[part 1 of 2: package /STELLANTIS/EPT/COMSWCs]
AUTOSAR XML (schema 4-2-2)
package /STELLANTIS/EPT/COMSWCs
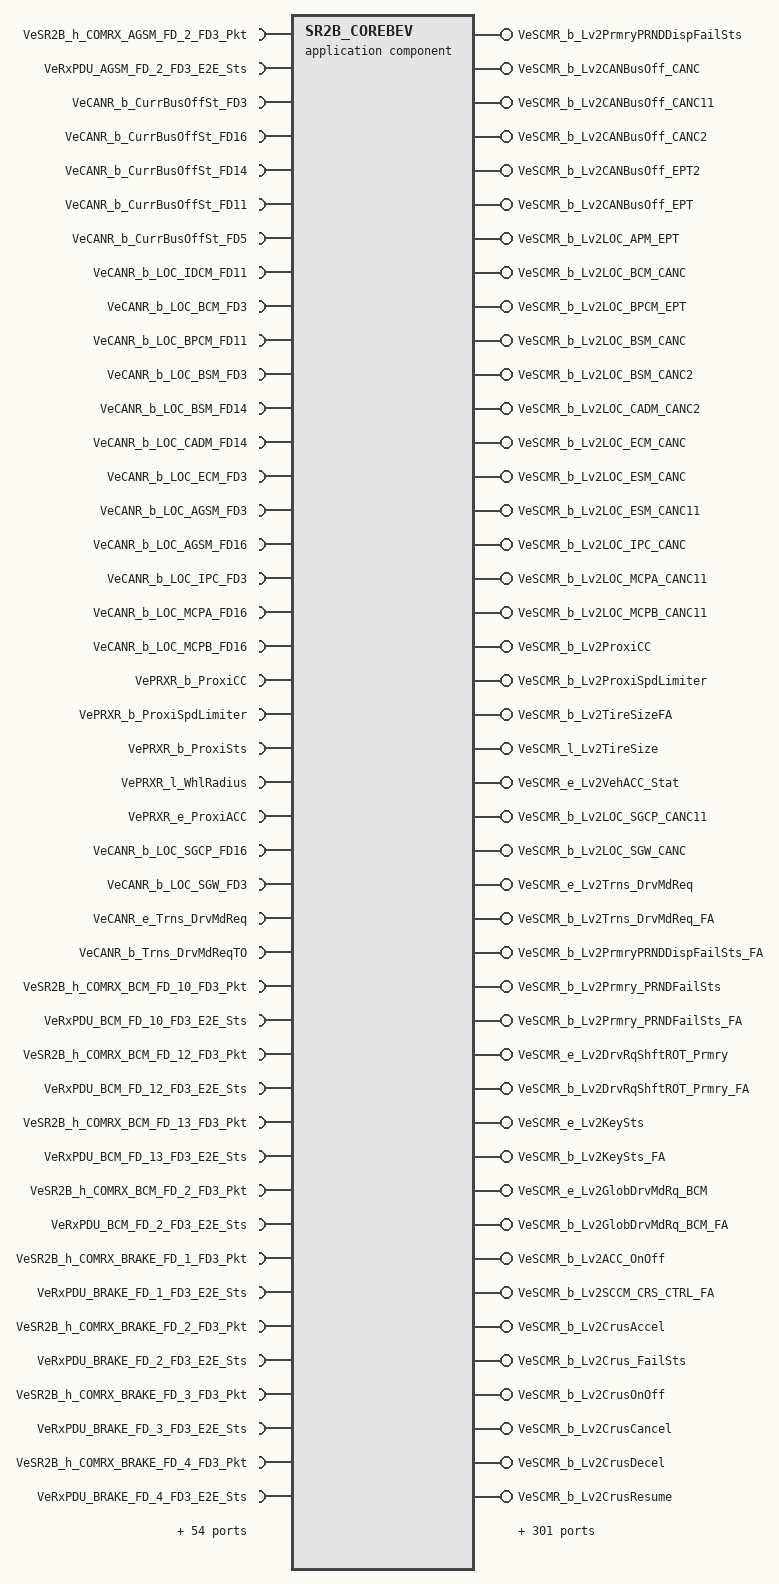
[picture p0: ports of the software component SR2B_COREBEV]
  application sw component type SR2B_COREBEV
    98 x require port:
      VeSR2B_h_COMRX_AGSM_FD_2_FD3_Pkt: nonqueued-receiver-com-spec{data-element=COMRX_AGSM_FD_2_FD3_Pkt, alive-timeout=0.2, init-value={short-label=DefaultInitValue_IDTRAGSM_FD_2_FD3_Pkt, fields=[0, 0, 0, 0, 0]}}, required-interface=VeSR2B_h_COMRX_AGSM_FD_2_FD3_Pkt
      VeRxPDU_AGSM_FD_2_FD3_E2E_Sts: required-com-specs=[{data-element=E2ECheckSts, init-value=0}, {data-element=OpRetVal, init-value=0}], required-interface=VeRxPDU_AGSM_FD_2_FD3_E2E_Sts
      VeCANR_b_CurrBusOffSt_FD3: nonqueued-receiver-com-spec{data-element=VeCANR_b_CurrBusOffSt_FD3, init-value=0}, required-interface=VeCANR_b_CurrBusOffSt_FD3
      VeCANR_b_CurrBusOffSt_FD16: nonqueued-receiver-com-spec{data-element=VeCANR_b_CurrBusOffSt_FD16, init-value=0}, required-interface=VeCANR_b_CurrBusOffSt_FD16
      VeCANR_b_CurrBusOffSt_FD14: nonqueued-receiver-com-spec{data-element=VeCANR_b_CurrBusOffSt_FD14, init-value=0}, required-interface=VeCANR_b_CurrBusOffSt_FD14
      VeCANR_b_CurrBusOffSt_FD11: nonqueued-receiver-com-spec{data-element=VeCANR_b_CurrBusOffSt_FD11, init-value=0}, required-interface=VeCANR_b_CurrBusOffSt_FD11
      VeCANR_b_CurrBusOffSt_FD5: nonqueued-receiver-com-spec{data-element=VeCANR_b_CurrBusOffSt_FD5, init-value=0}, required-interface=VeCANR_b_CurrBusOffSt_FD5
      VeCANR_b_LOC_IDCM_FD11: nonqueued-receiver-com-spec{data-element=VeCANR_b_LOC_IDCM_FD11, init-value=0}, required-interface=VeCANR_b_LOC_IDCM_FD11
      VeCANR_b_LOC_BCM_FD3: nonqueued-receiver-com-spec{data-element=VeCANR_b_LOC_BCM_FD3, init-value=0}, required-interface=VeCANR_b_LOC_BCM_FD3
      VeCANR_b_LOC_BPCM_FD11: nonqueued-receiver-com-spec{data-element=VeCANR_b_LOC_BPCM_FD11, init-value=0}, required-interface=VeCANR_b_LOC_BPCM_FD11
      VeCANR_b_LOC_BSM_FD3: nonqueued-receiver-com-spec{data-element=VeCANR_b_LOC_BSM_FD3, init-value=0}, required-interface=VeCANR_b_LOC_BSM_FD3
      VeCANR_b_LOC_BSM_FD14: nonqueued-receiver-com-spec{data-element=VeCANR_b_LOC_BSM_FD14, init-value=0}, required-interface=VeCANR_b_LOC_BSM_FD14
      VeCANR_b_LOC_CADM_FD14: nonqueued-receiver-com-spec{data-element=VeCANR_b_LOC_CADM_FD14, init-value=0}, required-interface=VeCANR_b_LOC_CADM_FD14
      VeCANR_b_LOC_ECM_FD3: nonqueued-receiver-com-spec{data-element=VeCANR_b_LOC_ECM_FD3, init-value=0}, required-interface=VeCANR_b_LOC_ECM_FD3
      VeCANR_b_LOC_AGSM_FD3: nonqueued-receiver-com-spec{data-element=VeCANR_b_LOC_AGSM_FD3, init-value=0}, required-interface=VeCANR_b_LOC_AGSM_FD3
      VeCANR_b_LOC_AGSM_FD16: nonqueued-receiver-com-spec{data-element=VeCANR_b_LOC_AGSM_FD16, init-value=0}, required-interface=VeCANR_b_LOC_AGSM_FD16
      VeCANR_b_LOC_IPC_FD3: nonqueued-receiver-com-spec{data-element=VeCANR_b_LOC_IPC_FD3, init-value=0}, required-interface=VeCANR_b_LOC_IPC_FD3
      VeCANR_b_LOC_MCPA_FD16: nonqueued-receiver-com-spec{data-element=VeCANR_b_LOC_MCPA_FD16, init-value=0}, required-interface=VeCANR_b_LOC_MCPA_FD16
      VeCANR_b_LOC_MCPB_FD16: nonqueued-receiver-com-spec{data-element=VeCANR_b_LOC_MCPB_FD16, init-value=0}, required-interface=VeCANR_b_LOC_MCPB_FD16
      VePRXR_b_ProxiCC: nonqueued-receiver-com-spec{data-element=Value, init-value=0}, required-interface=VePRXR_b_ProxiCC
      VePRXR_b_ProxiSpdLimiter: nonqueued-receiver-com-spec{data-element=Value, init-value=0}, required-interface=VePRXR_b_ProxiSpdLimiter
      VePRXR_b_ProxiSts: nonqueued-receiver-com-spec{data-element=Value, init-value=0}, required-interface=VePRXR_b_ProxiSts
      VePRXR_l_WhlRadius: nonqueued-receiver-com-spec{data-element=Value, init-value=0}, required-interface=VePRXR_l_WhlRadius
      VePRXR_e_ProxiACC: nonqueued-receiver-com-spec{data-element=Value, init-value=CePRXR_e_ACC_Absent}, required-interface=VePRXR_e_ProxiACC
      VeCANR_b_LOC_SGCP_FD16: nonqueued-receiver-com-spec{data-element=VeCANR_b_LOC_SGCP_FD16, init-value=0}, required-interface=VeCANR_b_LOC_SGCP_FD16
      VeCANR_b_LOC_SGW_FD3: nonqueued-receiver-com-spec{data-element=VeCANR_b_LOC_SGW_FD3, init-value=0}, required-interface=VeCANR_b_LOC_SGW_FD3
      VeCANR_e_Trns_DrvMdReq: nonqueued-receiver-com-spec{data-element=VeCANR_e_Trns_DrvMdReq, handle-never-received=true, init-value=0}, required-interface=VeCANR_e_Trns_DrvMdReq
      VeCANR_b_Trns_DrvMdReqTO: nonqueued-receiver-com-spec{data-element=VeCANR_b_Trns_DrvMdReqTO, init-value=0}, required-interface=VeCANR_b_Trns_DrvMdReqTO
      VeSR2B_h_COMRX_BCM_FD_10_FD3_Pkt: nonqueued-receiver-com-spec{data-element=COMRX_BCM_FD_10_FD3_Pkt, alive-timeout=5, init-value={short-label=DefaultInitValue_IDTRBCM_FD_10_FD3_Pkt, fields=[0, 0, 0, 0, 0]}}, required-interface=VeSR2B_h_COMRX_BCM_FD_10_FD3_Pkt
      VeRxPDU_BCM_FD_10_FD3_E2E_Sts: required-com-specs=[{data-element=E2ECheckSts, init-value=0}, {data-element=OpRetVal, init-value=0}], required-interface=VeRxPDU_BCM_FD_10_FD3_E2E_Sts
      VeSR2B_h_COMRX_BCM_FD_12_FD3_Pkt: nonqueued-receiver-com-spec{data-element=COMRX_BCM_FD_12_FD3_Pkt, alive-timeout=1, init-value={short-label=DefaultInitValue_IDTRBCM_FD_12_FD3_Pkt, fields=[0, 0, 0, 0, 0, 0, 0, 0, 0, 0, 0, 0, 0, 0, 0, 0, 0]}}, required-interface=VeSR2B_h_COMRX_BCM_FD_12_FD3_Pkt
      VeRxPDU_BCM_FD_12_FD3_E2E_Sts: required-com-specs=[{data-element=E2ECheckSts, init-value=0}, {data-element=OpRetVal, init-value=0}], required-interface=VeRxPDU_BCM_FD_12_FD3_E2E_Sts
      VeSR2B_h_COMRX_BCM_FD_13_FD3_Pkt: nonqueued-receiver-com-spec{data-element=COMRX_BCM_FD_13_FD3_Pkt, init-value={short-label=DefaultInitValue_IDTRBCM_FD_13_FD3_Pkt, fields=[0, 0, 0, 0, 0, 0, 0, 0, 0]}}, required-interface=VeSR2B_h_COMRX_BCM_FD_13_FD3_Pkt
      VeRxPDU_BCM_FD_13_FD3_E2E_Sts: required-com-specs=[{data-element=E2ECheckSts, init-value=0}, {data-element=OpRetVal, init-value=0}], required-interface=VeRxPDU_BCM_FD_13_FD3_E2E_Sts
      VeSR2B_h_COMRX_BCM_FD_2_FD3_Pkt: nonqueued-receiver-com-spec{data-element=COMRX_BCM_FD_2_FD3_Pkt, alive-timeout=0.1, init-value={short-label=DefaultInitValue_IDTRBCM_FD_2_FD3_Pkt, fields=[0, 0, 0, 0, 0]}}, required-interface=VeSR2B_h_COMRX_BCM_FD_2_FD3_Pkt
      VeRxPDU_BCM_FD_2_FD3_E2E_Sts: required-com-specs=[{data-element=E2ECheckSts, init-value=0}, {data-element=OpRetVal, init-value=0}], required-interface=VeRxPDU_BCM_FD_2_FD3_E2E_Sts
      VeSR2B_h_COMRX_BRAKE_FD_1_FD3_Pkt: nonqueued-receiver-com-spec{data-element=COMRX_BRAKE_FD_1_FD3_Pkt, alive-timeout=0.2, init-value={short-label=DefaultInitValue_IDTRBRAKE_FD_1_FD3_Pkt, fields=[0, 0, 0, 0, 0, 0, 0, 0, 0, 0, 0, 0, 0]}}, required-interface=VeSR2B_h_COMRX_BRAKE_FD_1_FD3_Pkt
      VeRxPDU_BRAKE_FD_1_FD3_E2E_Sts: required-com-specs=[{data-element=E2ECheckSts, init-value=0}, {data-element=OpRetVal, init-value=0}], required-interface=VeRxPDU_BRAKE_FD_1_FD3_E2E_Sts
      VeSR2B_h_COMRX_BRAKE_FD_2_FD3_Pkt: nonqueued-receiver-com-spec{data-element=COMRX_BRAKE_FD_2_FD3_Pkt, alive-timeout=0.1, init-value={short-label=DefaultInitValue_IDTRBRAKE_FD_2_FD3_Pkt, fields=[0, 0, 0, 0, 0, 0, 0, 0, 0, 0, 0, 0, 0, 0, 0, 0, 0, 0]}}, required-interface=VeSR2B_h_COMRX_BRAKE_FD_2_FD3_Pkt
      VeRxPDU_BRAKE_FD_2_FD3_E2E_Sts: required-com-specs=[{data-element=E2ECheckSts, init-value=0}, {data-element=OpRetVal, init-value=0}], required-interface=VeRxPDU_BRAKE_FD_2_FD3_E2E_Sts
      VeSR2B_h_COMRX_BRAKE_FD_3_FD3_Pkt: nonqueued-receiver-com-spec{data-element=COMRX_BRAKE_FD_3_FD3_Pkt, alive-timeout=0.1, init-value={short-label=DefaultInitValue_IDTRBRAKE_FD_3_FD3_Pkt, fields=[0, 0, 0, 0, 0, 0, 0, 0, 0, 0, 0, 0, 0, 0, 0, 0]}}, required-interface=VeSR2B_h_COMRX_BRAKE_FD_3_FD3_Pkt
      VeRxPDU_BRAKE_FD_3_FD3_E2E_Sts: required-com-specs=[{data-element=E2ECheckSts, init-value=0}, {data-element=OpRetVal, init-value=0}], required-interface=VeRxPDU_BRAKE_FD_3_FD3_E2E_Sts
      VeSR2B_h_COMRX_BRAKE_FD_4_FD3_Pkt: nonqueued-receiver-com-spec{data-element=COMRX_BRAKE_FD_4_FD3_Pkt, alive-timeout=1, init-value={short-label=DefaultInitValue_IDTRBRAKE_FD_4_FD3_Pkt, fields=[0, 0, 0, 0]}}, required-interface=VeSR2B_h_COMRX_BRAKE_FD_4_FD3_Pkt
      VeRxPDU_BRAKE_FD_4_FD3_E2E_Sts: required-com-specs=[{data-element=E2ECheckSts, init-value=0}, {data-element=OpRetVal, init-value=0}], required-interface=VeRxPDU_BRAKE_FD_4_FD3_E2E_Sts
      VeSR2B_h_COMRX_BRAKE_FD_5_FD3_Pkt: nonqueued-receiver-com-spec{data-element=COMRX_BRAKE_FD_5_FD3_Pkt, alive-timeout=5, init-value={short-label=DefaultInitValue_IDTRBRAKE_FD_5_FD3_Pkt, fields=[0, 0, 0, 0, 0, 0, 0]}}, required-interface=VeSR2B_h_COMRX_BRAKE_FD_5_FD3_Pkt
      VeRxPDU_BRAKE_FD_5_FD3_E2E_Sts: required-com-specs=[{data-element=E2ECheckSts, init-value=0}, {data-element=OpRetVal, init-value=0}], required-interface=VeRxPDU_BRAKE_FD_5_FD3_E2E_Sts
      VeSR2B_h_COMRX_BRAKE_FD_6_FD3_Pkt: nonqueued-receiver-com-spec{data-element=COMRX_BRAKE_FD_6_FD3_Pkt, alive-timeout=0.1, init-value={short-label=DefaultInitValue_IDTRBRAKE_FD_6_FD3_Pkt, fields=[0, 0, 0, 0, 0, 0, 0, 0, 0, 0, 0, 0, 0, 0]}}, required-interface=VeSR2B_h_COMRX_BRAKE_FD_6_FD3_Pkt
      VeRxPDU_BRAKE_FD_6_FD3_E2E_Sts: required-com-specs=[{data-element=E2ECheckSts, init-value=0}, {data-element=OpRetVal, init-value=0}], required-interface=VeRxPDU_BRAKE_FD_6_FD3_E2E_Sts
      VeSR2B_h_COMRX_BRAKE_FD_7_FD3_Pkt: nonqueued-receiver-com-spec{data-element=COMRX_BRAKE_FD_7_FD3_Pkt, alive-timeout=0.2, init-value={short-label=DefaultInitValue_IDTRBRAKE_FD_7_FD3_Pkt, fields=[0, 0, 0, 0, 0, 0]}}, required-interface=VeSR2B_h_COMRX_BRAKE_FD_7_FD3_Pkt
      VeRxPDU_BRAKE_FD_7_FD3_E2E_Sts: required-com-specs=[{data-element=E2ECheckSts, init-value=0}, {data-element=OpRetVal, init-value=0}], required-interface=VeRxPDU_BRAKE_FD_7_FD3_E2E_Sts
      VeSR2B_h_COMRX_ENGINE_HYBD_FD_1_FD3_Pkt: nonqueued-receiver-com-spec{data-element=COMRX_ENGINE_HYBD_FD_1_FD3_Pkt, alive-timeout=0.1, init-value={short-label=DefaultInitValue_IDTRENGINE_HYBD_FD_1_FD3_Pkt, fields=[0, 0, 0, 0, 0, 0, 0, 0, 0, 0, 0, 0]}}, required-interface=VeSR2B_h_COMRX_ENGINE_HYBD_FD_1_FD3_Pkt
      VeRxPDU_ENGINE_HYBD_FD_1_FD3_E2E_Sts: required-com-specs=[{data-element=E2ECheckSts, init-value=0}, {data-element=OpRetVal, init-value=0}], required-interface=VeRxPDU_ENGINE_HYBD_FD_1_FD3_E2E_Sts
      VeSR2B_h_COMRX_IPC_VEHICLE_SETUP_FD3_Pkt: nonqueued-receiver-com-spec{data-element=COMRX_IPC_VEHICLE_SETUP_FD3_Pkt, alive-timeout=10, init-value={short-label=DefaultInitValue_IDTRIPC_VEHICLE_SETUP_FD3_Pkt, fields=[0, 0, 0, 0, 0, 0, 0]}}, required-interface=VeSR2B_h_COMRX_IPC_VEHICLE_SETUP_FD3_Pkt
      VeRxPDU_IPC_VEHICLE_SETUP_FD3_E2E_Sts: required-com-specs=[{data-element=E2ECheckSts, init-value=0}, {data-element=OpRetVal, init-value=0}], required-interface=VeRxPDU_IPC_VEHICLE_SETUP_FD3_E2E_Sts
      VeSR2B_h_COMRX_TELEMATIC_FD_5_FD3_Pkt: nonqueued-receiver-com-spec{data-element=COMRX_TELEMATIC_FD_5_FD3_Pkt, alive-timeout=10, init-value={short-label=DefaultInitValue_IDTRTELEMATIC_FD_5_FD3_Pkt, fields=0}}, required-interface=VeSR2B_h_COMRX_TELEMATIC_FD_5_FD3_Pkt
      VeRxPDU_TELEMATIC_FD_5_FD3_E2E_Sts: required-com-specs=[{data-element=E2ECheckSts, init-value=0}, {data-element=OpRetVal, init-value=0}], required-interface=VeRxPDU_TELEMATIC_FD_5_FD3_E2E_Sts
      VeSR2B_h_COMRX_APM_VDCM_FD11_Pkt: nonqueued-receiver-com-spec{data-element=COMRX_APM_VDCM_FD11_Pkt, alive-timeout=0.2, init-value={short-label=DefaultInitValue_IDTRAPM_VDCM_FD11_Pkt, fields=[0, 0, 0, 0, 0, 0, 0, 0, 0, 0, 0, 0, 0, 0, 0, 0, 0, 0, 0, 0, 0, 0, 0, 0, 0, 0]}}, required-interface=VeSR2B_h_COMRX_APM_VDCM_FD11_Pkt
      VeRxPDU_APM_VDCM_FD11_E2E_Sts: required-com-specs=[{data-element=E2ECheckSts, init-value=0}, {data-element=OpRetVal, init-value=0}], required-interface=VeRxPDU_APM_VDCM_FD11_E2E_Sts
      VeSR2B_h_COMRX_BATTERY_HV_POWERLIMITS_FD11_Pkt: nonqueued-receiver-com-spec{data-element=COMRX_BATTERY_HV_POWERLIMITS_FD11_Pkt, alive-timeout=0.1, init-value={short-label=DefaultInitValue_IDTRBATTERY_HV_POWERLIMITS_FD11_Pkt, fields=[0, 0, 0, 0, 0, 0, 0, 0, 0, 0, 0, 0, 0, 0, 0, 0]}}, required-interface=VeSR2B_h_COMRX_BATTERY_HV_POWERLIMITS_FD11_Pkt
      VeRxPDU_BATTERY_HV_POWERLIMITS_FD11_E2E_Sts: required-com-specs=[{data-element=E2ECheckSts, init-value=0}, {data-element=OpRetVal, init-value=0}], required-interface=VeRxPDU_BATTERY_HV_POWERLIMITS_FD11_E2E_Sts
      VeSR2B_h_COMRX_BATTERY_HV_STATUS1_FD11_Pkt: nonqueued-receiver-com-spec{data-element=COMRX_BATTERY_HV_STATUS1_FD11_Pkt, alive-timeout=0.1, init-value={short-label=DefaultInitValue_IDTRBATTERY_HV_STATUS1_FD11_Pkt, fields=[0, 0, 0, 0, 0, 0, 0, 0, 0, 0, 0, 0, 0, 0, 0, 0, 0, 0, 0, 0, 0, 0, 0, 0, 0, 0, 0, 0, 0, 0, 0, 0, 0, 0, 0, 0, 0, 0, 0, 0, 0]}}, required-interface=VeSR2B_h_COMRX_BATTERY_HV_STATUS1_FD11_Pkt
      VeRxPDU_BATTERY_HV_STATUS1_FD11_E2E_Sts: required-com-specs=[{data-element=E2ECheckSts, init-value=0}, {data-element=OpRetVal, init-value=0}], required-interface=VeRxPDU_BATTERY_HV_STATUS1_FD11_E2E_Sts
      VeSR2B_h_COMRX_HV_CHARGER1_FD11_Pkt: nonqueued-receiver-com-spec{data-element=COMRX_HV_CHARGER1_FD11_Pkt, alive-timeout=1, init-value={short-label=DefaultInitValue_IDTRHV_CHARGER1_FD11_Pkt, fields=[0, 0, 0, 0, 0, 0, 0, 0, 0, 0, 0, 0, 0, 0, 0, 0, 0, 0, 0, 0, 0, 0, 0, 0, 0, 0, 0, 0, 0, 0, 0, 0, 0, 0, 0, 0, 0]}}, required-interface=VeSR2B_h_COMRX_HV_CHARGER1_FD11_Pkt
      VeRxPDU_HV_CHARGER1_FD11_E2E_Sts: required-com-specs=[{data-element=E2ECheckSts, init-value=0}, {data-element=OpRetVal, init-value=0}], required-interface=VeRxPDU_HV_CHARGER1_FD11_E2E_Sts
      VeSR2B_h_COMRX_ADAS_FD_INFO_FD14_Pkt: nonqueued-receiver-com-spec{data-element=COMRX_ADAS_FD_INFO_FD14_Pkt, alive-timeout=0.1, init-value={short-label=DefaultInitValue_IDTRADAS_FD_INFO_FD14_Pkt, fields=[0, 0, 0, 0, 0, 0, 0, 0, 0]}}, required-interface=VeSR2B_h_COMRX_ADAS_FD_INFO_FD14_Pkt
      VeRxPDU_ADAS_FD_INFO_FD14_E2E_Sts: required-com-specs=[{data-element=E2ECheckSts, init-value=0}, {data-element=OpRetVal, init-value=0}], required-interface=VeRxPDU_ADAS_FD_INFO_FD14_E2E_Sts
      VeSR2B_h_COMRX_BRAKE_FD_1_FD14_Pkt: nonqueued-receiver-com-spec{data-element=COMRX_BRAKE_FD_1_FD14_Pkt, alive-timeout=0.2, init-value={short-label=DefaultInitValue_IDTRBRAKE_FD_1_FD14_Pkt, fields=[0, 0, 0, 0, 0, 0, 0, 0]}}, required-interface=VeSR2B_h_COMRX_BRAKE_FD_1_FD14_Pkt
      VeRxPDU_BRAKE_FD_1_FD14_E2E_Sts: required-com-specs=[{data-element=E2ECheckSts, init-value=0}, {data-element=OpRetVal, init-value=0}], required-interface=VeRxPDU_BRAKE_FD_1_FD14_E2E_Sts
      VeSR2B_h_COMRX_BRAKE_FD_2_FD14_Pkt: nonqueued-receiver-com-spec{data-element=COMRX_BRAKE_FD_2_FD14_Pkt, alive-timeout=0.1, init-value={short-label=DefaultInitValue_IDTRBRAKE_FD_2_FD14_Pkt, fields=[0, 0, 0, 0, 0, 0, 0, 0, 0]}}, required-interface=VeSR2B_h_COMRX_BRAKE_FD_2_FD14_Pkt
      VeRxPDU_BRAKE_FD_2_FD14_E2E_Sts: required-com-specs=[{data-element=E2ECheckSts, init-value=0}, {data-element=OpRetVal, init-value=0}], required-interface=VeRxPDU_BRAKE_FD_2_FD14_E2E_Sts
      VeSR2B_h_COMRX_BRAKE_FD_6_FD14_Pkt: nonqueued-receiver-com-spec{data-element=COMRX_BRAKE_FD_6_FD14_Pkt, alive-timeout=0.1, init-value={short-label=DefaultInitValue_IDTRBRAKE_FD_6_FD14_Pkt, fields=[0, 0, 0, 0, 0, 0, 0, 0, 0, 0]}}, required-interface=VeSR2B_h_COMRX_BRAKE_FD_6_FD14_Pkt
      VeRxPDU_BRAKE_FD_6_FD14_E2E_Sts: required-com-specs=[{data-element=E2ECheckSts, init-value=0}, {data-element=OpRetVal, init-value=0}], required-interface=VeRxPDU_BRAKE_FD_6_FD14_E2E_Sts
      VeSR2B_h_COMRX_BRAKE_FD_7_FD14_Pkt: nonqueued-receiver-com-spec{data-element=COMRX_BRAKE_FD_7_FD14_Pkt, alive-timeout=0.2, init-value={short-label=DefaultInitValue_IDTRBRAKE_FD_7_FD14_Pkt, fields=[0, 0, 0]}}, required-interface=VeSR2B_h_COMRX_BRAKE_FD_7_FD14_Pkt
      VeRxPDU_BRAKE_FD_7_FD14_E2E_Sts: required-com-specs=[{data-element=E2ECheckSts, init-value=0}, {data-element=OpRetVal, init-value=0}], required-interface=VeRxPDU_BRAKE_FD_7_FD14_E2E_Sts
      VeSR2B_h_COMRX_EPS_FD_1_FD14_Pkt: nonqueued-receiver-com-spec{data-element=COMRX_EPS_FD_1_FD14_Pkt, alive-timeout=0.1, init-value={short-label=DefaultInitValue_IDTREPS_FD_1_FD14_Pkt, fields=[0, 0, 0]}}, required-interface=VeSR2B_h_COMRX_EPS_FD_1_FD14_Pkt
      VeRxPDU_EPS_FD_1_FD14_E2E_Sts: required-com-specs=[{data-element=E2ECheckSts, init-value=0}, {data-element=OpRetVal, init-value=0}], required-interface=VeRxPDU_EPS_FD_1_FD14_E2E_Sts
      VeSR2B_h_COMRX_ORC_FD_3_FD14_Pkt: nonqueued-receiver-com-spec{data-element=COMRX_ORC_FD_3_FD14_Pkt, alive-timeout=0.1, init-value={short-label=DefaultInitValue_IDTRORC_FD_3_FD14_Pkt, fields=[0, 0, 0, 0, 0, 0]}}, required-interface=VeSR2B_h_COMRX_ORC_FD_3_FD14_Pkt
      VeRxPDU_ORC_FD_3_FD14_E2E_Sts: required-com-specs=[{data-element=E2ECheckSts, init-value=0}, {data-element=OpRetVal, init-value=0}], required-interface=VeRxPDU_ORC_FD_3_FD14_E2E_Sts
      VeSR2B_h_COMRX_AGSM_FD_2_FD16_Pkt: nonqueued-receiver-com-spec{data-element=COMRX_AGSM_FD_2_FD16_Pkt, alive-timeout=0.2, init-value={short-label=DefaultInitValue_IDTRAGSM_FD_2_FD16_Pkt, fields=[0, 0, 0, 0]}}, required-interface=VeSR2B_h_COMRX_AGSM_FD_2_FD16_Pkt
      VeRxPDU_AGSM_FD_2_FD16_E2E_Sts: required-com-specs=[{data-element=E2ECheckSts, init-value=0}, {data-element=OpRetVal, init-value=0}], required-interface=VeRxPDU_AGSM_FD_2_FD16_E2E_Sts
      VeSR2B_h_COMRX_ELSDM_FD_1_FD16_Pkt: nonqueued-receiver-com-spec{data-element=COMRX_ELSDM_FD_1_FD16_Pkt, alive-timeout=0.1, init-value={short-label=DefaultInitValue_IDTRELSDM_FD_1_FD16_Pkt, fields=[0, 0, 0, 0, 0, 0, 0, 0, 0, 0, 0, 0, 0, 0, 0, 0, 0, 0, 0, 0]}}, required-interface=VeSR2B_h_COMRX_ELSDM_FD_1_FD16_Pkt
      VeRxPDU_ELSDM_FD_1_FD16_E2E_Sts: required-com-specs=[{data-element=E2ECheckSts, init-value=0}, {data-element=OpRetVal, init-value=0}], required-interface=VeRxPDU_ELSDM_FD_1_FD16_E2E_Sts
      VeSR2B_h_COMRX_MCPA_PROPULSION_FD16_Pkt: nonqueued-receiver-com-spec{data-element=COMRX_MCPA_PROPULSION_FD16_Pkt, alive-timeout=0.1, init-value={short-label=DefaultInitValue_IDTRMCPA_PROPULSION_FD16_Pkt, fields=[0, 0, 0, 0, 0, 0, 0, 0, 0, 0, 0, 0, 0, 0, 0, 0, 0, 0, 0, 0, 0, 0, 0, 0, 0, 0]}}, required-interface=VeSR2B_h_COMRX_MCPA_PROPULSION_FD16_Pkt
      VeRxPDU_MCPA_PROPULSION_FD16_E2E_Sts: required-com-specs=[{data-element=E2ECheckSts, init-value=0}, {data-element=OpRetVal, init-value=0}], required-interface=VeRxPDU_MCPA_PROPULSION_FD16_E2E_Sts
      VeSR2B_h_COMRX_MCPB_PROPULSION_FD16_Pkt: nonqueued-receiver-com-spec{data-element=COMRX_MCPB_PROPULSION_FD16_Pkt, alive-timeout=0.1, init-value={short-label=DefaultInitValue_IDTRMCPB_PROPULSION_FD16_Pkt, fields=[0, 0, 0, 0, 0, 0, 0, 0, 0, 0, 0, 0, 0, 0, 0, 0, 0, 0, 0, 0, 0, 0, 0, 0, 0, 0, 0, 0, 0, 0, 0]}}, required-interface=VeSR2B_h_COMRX_MCPB_PROPULSION_FD16_Pkt
      VeRxPDU_MCPB_PROPULSION_FD16_E2E_Sts: required-com-specs=[{data-element=E2ECheckSts, init-value=0}, {data-element=OpRetVal, init-value=0}], required-interface=VeRxPDU_MCPB_PROPULSION_FD16_E2E_Sts
      VeSR2B_h_COMRX_APM_VDCM_FD5_Pkt: nonqueued-receiver-com-spec{data-element=COMRX_APM_VDCM_FD5_Pkt, alive-timeout=0.2, init-value={short-label=DefaultInitValue_IDTRAPM_VDCM_FD5_Pkt, fields=[0, 0, 0, 0, 0, 0, 0, 0, 0, 0, 0, 0, 0, 0, 0, 0, 0, 0, 0, 0, 0, 0, 0, 0, 0, 0]}}, required-interface=VeSR2B_h_COMRX_APM_VDCM_FD5_Pkt
      VeRxPDU_APM_VDCM_FD5_E2E_Sts: required-com-specs=[{data-element=E2ECheckSts, init-value=0}, {data-element=OpRetVal, init-value=0}], required-interface=VeRxPDU_APM_VDCM_FD5_E2E_Sts
      VeSR2B_h_COMRX_BATTERY_HV_POWERLIMITS_FD5_Pkt: nonqueued-receiver-com-spec{data-element=COMRX_BATTERY_HV_POWERLIMITS_FD5_Pkt, alive-timeout=0.1, init-value={short-label=DefaultInitValue_IDTRBATTERY_HV_POWERLIMITS_FD5_Pkt, fields=[0, 0, 0, 0, 0, 0, 0, 0, 0, 0, 0, 0, 0, 0, 0, 0]}}, required-interface=VeSR2B_h_COMRX_BATTERY_HV_POWERLIMITS_FD5_Pkt
      VeRxPDU_BATTERY_HV_POWERLIMITS_FD5_E2E_Sts: required-com-specs=[{data-element=E2ECheckSts, init-value=0}, {data-element=OpRetVal, init-value=0}], required-interface=VeRxPDU_BATTERY_HV_POWERLIMITS_FD5_E2E_Sts
      VeSR2B_h_COMRX_BATTERY_HV_STATUS1_FD5_Pkt: nonqueued-receiver-com-spec{data-element=COMRX_BATTERY_HV_STATUS1_FD5_Pkt, alive-timeout=0.1, init-value={short-label=DefaultInitValue_IDTRBATTERY_HV_STATUS1_FD5_Pkt, fields=[0, 0, 0, 0, 0, 0, 0, 0, 0, 0, 0, 0, 0, 0, 0, 0, 0, 0, 0, 0, 0, 0, 0, 0, 0, 0, 0, 0, 0, 0, 0, 0, 0, 0, 0, 0, 0, 0, 0, 0, 0]}}, required-interface=VeSR2B_h_COMRX_BATTERY_HV_STATUS1_FD5_Pkt
      VeRxPDU_BATTERY_HV_STATUS1_FD5_E2E_Sts: required-com-specs=[{data-element=E2ECheckSts, init-value=0}, {data-element=OpRetVal, init-value=0}], required-interface=VeRxPDU_BATTERY_HV_STATUS1_FD5_E2E_Sts
      VeSR2B_h_COMRX_HV_CHARGER1_FD5_Pkt: nonqueued-receiver-com-spec{data-element=COMRX_HV_CHARGER1_FD5_Pkt, alive-timeout=1, init-value={short-label=DefaultInitValue_IDTRHV_CHARGER1_FD5_Pkt, fields=[0, 0, 0, 0, 0, 0, 0, 0, 0, 0, 0, 0, 0, 0, 0, 0, 0, 0, 0, 0, 0, 0, 0, 0, 0, 0, 0, 0, 0, 0, 0, 0, 0, 0, 0, 0, 0]}}, required-interface=VeSR2B_h_COMRX_HV_CHARGER1_FD5_Pkt
      VeRxPDU_HV_CHARGER1_FD5_E2E_Sts: required-com-specs=[{data-element=E2ECheckSts, init-value=0}, {data-element=OpRetVal, init-value=0}], required-interface=VeRxPDU_HV_CHARGER1_FD5_E2E_Sts
      VeSR2B_h_COMRX_MCPA_PROPULSION_FD5_Pkt: nonqueued-receiver-com-spec{data-element=COMRX_MCPA_PROPULSION_FD5_Pkt, alive-timeout=0.1, init-value={short-label=DefaultInitValue_IDTRMCPA_PROPULSION_FD5_Pkt, fields=[0, 0, 0, 0, 0, 0, 0, 0, 0, 0, 0, 0, 0, 0, 0, 0, 0, 0, 0, 0, 0, 0, 0, 0, 0, 0]}}, required-interface=VeSR2B_h_COMRX_MCPA_PROPULSION_FD5_Pkt
      VeRxPDU_MCPA_PROPULSION_FD5_E2E_Sts: required-com-specs=[{data-element=E2ECheckSts, init-value=0}, {data-element=OpRetVal, init-value=0}], required-interface=VeRxPDU_MCPA_PROPULSION_FD5_E2E_Sts
      VeSR2B_h_COMRX_MCPB_PROPULSION_FD5_Pkt: nonqueued-receiver-com-spec{data-element=COMRX_MCPB_PROPULSION_FD5_Pkt, alive-timeout=0.1, init-value={short-label=DefaultInitValue_IDTRMCPB_PROPULSION_FD5_Pkt, fields=[0, 0, 0, 0, 0, 0, 0, 0, 0, 0, 0, 0, 0, 0, 0, 0, 0, 0, 0, 0, 0, 0, 0, 0, 0, 0, 0, 0, 0, 0, 0]}}, required-interface=VeSR2B_h_COMRX_MCPB_PROPULSION_FD5_Pkt
      VeRxPDU_MCPB_PROPULSION_FD5_E2E_Sts: required-com-specs=[{data-element=E2ECheckSts, init-value=0}, {data-element=OpRetVal, init-value=0}], required-interface=VeRxPDU_MCPB_PROPULSION_FD5_E2E_Sts
    345 x provide port:
      VeSCMR_b_Lv2PrmryPRNDDispFailSts: nonqueued-sender-com-spec{data-element=Value, init-value=0}, provided-interface=VeSCMR_b_Lv2PrmryPRNDDispFailSts
      VeSCMR_b_Lv2CANBusOff_CANC: nonqueued-sender-com-spec{data-element=Value, init-value=0}, provided-interface=VeSCMR_b_Lv2CANBusOff_CANC
      VeSCMR_b_Lv2CANBusOff_CANC11: nonqueued-sender-com-spec{data-element=Value, init-value=0}, provided-interface=VeSCMR_b_Lv2CANBusOff_CANC11
      VeSCMR_b_Lv2CANBusOff_CANC2: nonqueued-sender-com-spec{data-element=Value, init-value=0}, provided-interface=VeSCMR_b_Lv2CANBusOff_CANC2
      VeSCMR_b_Lv2CANBusOff_EPT2: nonqueued-sender-com-spec{data-element=Value, init-value=0}, provided-interface=VeSCMR_b_Lv2CANBusOff_EPT2
      VeSCMR_b_Lv2CANBusOff_EPT: nonqueued-sender-com-spec{data-element=Value, init-value=0}, provided-interface=VeSCMR_b_Lv2CANBusOff_EPT
      VeSCMR_b_Lv2LOC_APM_EPT: nonqueued-sender-com-spec{data-element=Value, init-value=0}, provided-interface=VeSCMR_b_Lv2LOC_APM_EPT
      VeSCMR_b_Lv2LOC_BCM_CANC: nonqueued-sender-com-spec{data-element=Value, init-value=0}, provided-interface=VeSCMR_b_Lv2LOC_BCM_CANC
      VeSCMR_b_Lv2LOC_BPCM_EPT: nonqueued-sender-com-spec{data-element=Value, init-value=0}, provided-interface=VeSCMR_b_Lv2LOC_BPCM_EPT
      VeSCMR_b_Lv2LOC_BSM_CANC: nonqueued-sender-com-spec{data-element=Value, init-value=0}, provided-interface=VeSCMR_b_Lv2LOC_BSM_CANC
      VeSCMR_b_Lv2LOC_BSM_CANC2: nonqueued-sender-com-spec{data-element=Value, init-value=0}, provided-interface=VeSCMR_b_Lv2LOC_BSM_CANC2
      VeSCMR_b_Lv2LOC_CADM_CANC2: nonqueued-sender-com-spec{data-element=Value, init-value=0}, provided-interface=VeSCMR_b_Lv2LOC_CADM_CANC2
      VeSCMR_b_Lv2LOC_ECM_CANC: nonqueued-sender-com-spec{data-element=Value, init-value=0}, provided-interface=VeSCMR_b_Lv2LOC_ECM_CANC
      VeSCMR_b_Lv2LOC_ESM_CANC: nonqueued-sender-com-spec{data-element=Value, init-value=0}, provided-interface=VeSCMR_b_Lv2LOC_ESM_CANC
      VeSCMR_b_Lv2LOC_ESM_CANC11: nonqueued-sender-com-spec{data-element=Value, init-value=0}, provided-interface=VeSCMR_b_Lv2LOC_ESM_CANC11
      VeSCMR_b_Lv2LOC_IPC_CANC: nonqueued-sender-com-spec{data-element=Value, init-value=0}, provided-interface=VeSCMR_b_Lv2LOC_IPC_CANC
      VeSCMR_b_Lv2LOC_MCPA_CANC11: nonqueued-sender-com-spec{data-element=Value, init-value=0}, provided-interface=VeSCMR_b_Lv2LOC_MCPA_CANC11
      VeSCMR_b_Lv2LOC_MCPB_CANC11: nonqueued-sender-com-spec{data-element=Value, init-value=0}, provided-interface=VeSCMR_b_Lv2LOC_MCPB_CANC11
      VeSCMR_b_Lv2ProxiCC: nonqueued-sender-com-spec{data-element=Value, init-value=0}, provided-interface=VeSCMR_b_Lv2ProxiCC
      VeSCMR_b_Lv2ProxiSpdLimiter: nonqueued-sender-com-spec{data-element=Value, init-value=0}, provided-interface=VeSCMR_b_Lv2ProxiSpdLimiter
      VeSCMR_b_Lv2TireSizeFA: nonqueued-sender-com-spec{data-element=Value, init-value=0}, provided-interface=VeSCMR_b_Lv2TireSizeFA
      VeSCMR_l_Lv2TireSize: nonqueued-sender-com-spec{data-element=Value, init-value=0}, provided-interface=VeSCMR_l_Lv2TireSize
      VeSCMR_e_Lv2VehACC_Stat: nonqueued-sender-com-spec{data-element=Value, init-value=CeCSMR_e_Lv2Absent}, provided-interface=VeSCMR_e_Lv2VehACC_Stat
      VeSCMR_b_Lv2LOC_SGCP_CANC11: nonqueued-sender-com-spec{data-element=Value, init-value=0}, provided-interface=VeSCMR_b_Lv2LOC_SGCP_CANC11
      VeSCMR_b_Lv2LOC_SGW_CANC: nonqueued-sender-com-spec{data-element=Value, init-value=0}, provided-interface=VeSCMR_b_Lv2LOC_SGW_CANC
      VeSCMR_e_Lv2Trns_DrvMdReq: nonqueued-sender-com-spec{data-element=Value, init-value=0}, provided-interface=VeSCMR_e_Lv2Trns_DrvMdReq
      VeSCMR_b_Lv2Trns_DrvMdReq_FA: nonqueued-sender-com-spec{data-element=Value, init-value=0}, provided-interface=VeSCMR_b_Lv2Trns_DrvMdReq_FA
      VeSCMR_b_Lv2PrmryPRNDDispFailSts_FA: nonqueued-sender-com-spec{data-element=Value, init-value=0}, provided-interface=VeSCMR_b_Lv2PrmryPRNDDispFailSts_FA
      VeSCMR_b_Lv2Prmry_PRNDFailSts: nonqueued-sender-com-spec{data-element=Value, init-value=0}, provided-interface=VeSCMR_b_Lv2Prmry_PRNDFailSts
      VeSCMR_b_Lv2Prmry_PRNDFailSts_FA: nonqueued-sender-com-spec{data-element=Value, init-value=0}, provided-interface=VeSCMR_b_Lv2Prmry_PRNDFailSts_FA
      VeSCMR_e_Lv2DrvRqShftROT_Prmry: nonqueued-sender-com-spec{data-element=Value, init-value=CeGSMR_e_PRNDInit}, provided-interface=VeSCMR_e_Lv2DrvRqShftROT_Prmry
      VeSCMR_b_Lv2DrvRqShftROT_Prmry_FA: nonqueued-sender-com-spec{data-element=Value, init-value=0}, provided-interface=VeSCMR_b_Lv2DrvRqShftROT_Prmry_FA
      VeSCMR_e_Lv2KeySts: nonqueued-sender-com-spec{data-element=Value, init-value=CeLTIR_e_IGN_LK}, provided-interface=VeSCMR_e_Lv2KeySts
      VeSCMR_b_Lv2KeySts_FA: nonqueued-sender-com-spec{data-element=Value, init-value=0}, provided-interface=VeSCMR_b_Lv2KeySts_FA
      VeSCMR_e_Lv2GlobDrvMdRq_BCM: nonqueued-sender-com-spec{data-element=Value, init-value=0}, provided-interface=VeSCMR_e_Lv2GlobDrvMdRq_BCM
      VeSCMR_b_Lv2GlobDrvMdRq_BCM_FA: nonqueued-sender-com-spec{data-element=Value, init-value=0}, provided-interface=VeSCMR_b_Lv2GlobDrvMdRq_BCM_FA
      VeSCMR_b_Lv2ACC_OnOff: nonqueued-sender-com-spec{data-element=Value, init-value=0}, provided-interface=VeSCMR_b_Lv2ACC_OnOff
      VeSCMR_b_Lv2SCCM_CRS_CTRL_FA: nonqueued-sender-com-spec{data-element=Value, init-value=0}, provided-interface=VeSCMR_b_Lv2SCCM_CRS_CTRL_FA
      VeSCMR_b_Lv2CrusAccel: nonqueued-sender-com-spec{data-element=Value, init-value=0}, provided-interface=VeSCMR_b_Lv2CrusAccel
      VeSCMR_b_Lv2Crus_FailSts: nonqueued-sender-com-spec{data-element=Value, init-value=0}, provided-interface=VeSCMR_b_Lv2Crus_FailSts
      VeSCMR_b_Lv2CrusOnOff: nonqueued-sender-com-spec{data-element=Value, init-value=0}, provided-interface=VeSCMR_b_Lv2CrusOnOff
      VeSCMR_b_Lv2CrusCancel: nonqueued-sender-com-spec{data-element=Value, init-value=0}, provided-interface=VeSCMR_b_Lv2CrusCancel
      VeSCMR_b_Lv2CrusDecel: nonqueued-sender-com-spec{data-element=Value, init-value=0}, provided-interface=VeSCMR_b_Lv2CrusDecel
      VeSCMR_b_Lv2CrusResume: nonqueued-sender-com-spec{data-element=Value, init-value=0}, provided-interface=VeSCMR_b_Lv2CrusResume
      VeSCMR_y_Lv2OperationalModeSts: nonqueued-sender-com-spec{data-element=Value, init-value=0}, provided-interface=VeSCMR_y_Lv2OperationalModeSts
      VeSCMR_b_Lv2OperationalModeSts_FA: nonqueued-sender-com-spec{data-element=Value, init-value=0}, provided-interface=VeSCMR_b_Lv2OperationalModeSts_FA
      VeSCMR_b_Lv2RmtStrtActv: nonqueued-sender-com-spec{data-element=Value, init-value=0}, provided-interface=VeSCMR_b_Lv2RmtStrtActv
      VeSCMR_b_Lv2RmtStrtActv_FA: nonqueued-sender-com-spec{data-element=Value, init-value=0}, provided-interface=VeSCMR_b_Lv2RmtStrtActv_FA
      VeSCMR_M_Lv2BrkTrq: nonqueued-sender-com-spec{data-element=Value, init-value=0}, provided-interface=VeSCMR_M_Lv2BrkTrq
      VeSCMR_b_Lv2BrkTrq_FA: nonqueued-sender-com-spec{data-element=Value, init-value=0}, provided-interface=VeSCMR_b_Lv2BrkTrq_FA
      VeSCMR_M_Lv2BrkTrqDriver: nonqueued-sender-com-spec{data-element=Value, init-value=0}, provided-interface=VeSCMR_M_Lv2BrkTrqDriver
      VeSCMR_b_Lv2BrkTrqDriver_FA: nonqueued-sender-com-spec{data-element=Value, init-value=0}, provided-interface=VeSCMR_b_Lv2BrkTrqDriver_FA
      VeSCMR_b_Lv2ABSActive: nonqueued-sender-com-spec{data-element=Value, init-value=0}, provided-interface=VeSCMR_b_Lv2ABSActive
      VeSCMR_b_Lv2ABSActive_FA: nonqueued-sender-com-spec{data-element=Value, init-value=0}, provided-interface=VeSCMR_b_Lv2ABSActive_FA
      VeSCMR_e_Lv2BrkMaxRgnReady: nonqueued-sender-com-spec{data-element=Value, init-value=0}, provided-interface=VeSCMR_e_Lv2BrkMaxRgnReady
      VeSCMR_b_Lv2BrkMaxRgnReady_FA: nonqueued-sender-com-spec{data-element=Value, init-value=0}, provided-interface=VeSCMR_b_Lv2BrkMaxRgnReady_FA
      VeSCMR_p_Lv2BrakeBoostPressure: nonqueued-sender-com-spec{data-element=Value, init-value=0}, provided-interface=VeSCMR_p_Lv2BrakeBoostPressure
      VeSCMR_b_Lv2BrkBoostPressure_FA: nonqueued-sender-com-spec{data-element=Value, init-value=0}, provided-interface=VeSCMR_b_Lv2BrkBoostPressure_FA
      VeSCMR_b_Lv2ESC_Active: nonqueued-sender-com-spec{data-element=Value, init-value=0}, provided-interface=VeSCMR_b_Lv2ESC_Active
      VeSCMR_b_Lv2ESC_Active_FA: nonqueued-sender-com-spec{data-element=Value, init-value=0}, provided-interface=VeSCMR_b_Lv2ESC_Active_FA
      VeSCMR_e_Lv2ParkingGearShiftReq_BSM: nonqueued-sender-com-spec{data-element=Value, init-value=0}, provided-interface=VeSCMR_e_Lv2ParkingGearShiftReq_BSM
      VeSCMR_b_Lv2ParkingGearShiftReq_BSM_FA: nonqueued-sender-com-spec{data-element=Value, init-value=0}, provided-interface=VeSCMR_b_Lv2ParkingGearShiftReq_BSM_FA
      VeSCMR_v_Lv2VehSpdCANC: nonqueued-sender-com-spec{data-element=Value, init-value=0}, provided-interface=VeSCMR_v_Lv2VehSpdCANC
      VeSCMR_b_Lv2VehSpdCANC_FA: nonqueued-sender-com-spec{data-element=Value, init-value=0}, provided-interface=VeSCMR_b_Lv2VehSpdCANC_FA
      VeSCMR_n_Lv2WhlFL_RPS: nonqueued-sender-com-spec{data-element=Value, init-value=0}, provided-interface=VeSCMR_n_Lv2WhlFL_RPS
      VeSCMR_b_Lv2WhlFL_RPS_FA: nonqueued-sender-com-spec{data-element=Value, init-value=0}, provided-interface=VeSCMR_b_Lv2WhlFL_RPS_FA
      VeSCMR_n_Lv2WhlFR_RPS: nonqueued-sender-com-spec{data-element=Value, init-value=0}, provided-interface=VeSCMR_n_Lv2WhlFR_RPS
      VeSCMR_b_Lv2WhlFR_RPS_FA: nonqueued-sender-com-spec{data-element=Value, init-value=0}, provided-interface=VeSCMR_b_Lv2WhlFR_RPS_FA
      VeSCMR_e_Lv2WhlDirFL_Stat: nonqueued-sender-com-spec{data-element=Value, init-value=0}, provided-interface=VeSCMR_e_Lv2WhlDirFL_Stat
      VeSCMR_b_Lv2WhlDirFL_Stat_FA: nonqueued-sender-com-spec{data-element=Value, init-value=0}, provided-interface=VeSCMR_b_Lv2WhlDirFL_Stat_FA
      VeSCMR_b_Lv2WhlSensFailFL: nonqueued-sender-com-spec{data-element=Value, init-value=0}, provided-interface=VeSCMR_b_Lv2WhlSensFailFL
      VeSCMR_b_Lv2WhlSensFailFL_FA: nonqueued-sender-com-spec{data-element=Value, init-value=0}, provided-interface=VeSCMR_b_Lv2WhlSensFailFL_FA
      VeSCMR_n_Lv2WhlFL_Spd: nonqueued-sender-com-spec{data-element=Value, init-value=0}, provided-interface=VeSCMR_n_Lv2WhlFL_Spd
      VeSCMR_b_Lv2WhlFL_Spd_FA: nonqueued-sender-com-spec{data-element=Value, init-value=0}, provided-interface=VeSCMR_b_Lv2WhlFL_Spd_FA
      VeSCMR_e_Lv2WhlDirRL_Stat: nonqueued-sender-com-spec{data-element=Value, init-value=0}, provided-interface=VeSCMR_e_Lv2WhlDirRL_Stat
      VeSCMR_b_Lv2WhlDirRL_Stat_FA: nonqueued-sender-com-spec{data-element=Value, init-value=0}, provided-interface=VeSCMR_b_Lv2WhlDirRL_Stat_FA
      VeSCMR_b_Lv2WhlSensFailRL: nonqueued-sender-com-spec{data-element=Value, init-value=0}, provided-interface=VeSCMR_b_Lv2WhlSensFailRL
      VeSCMR_b_Lv2WhlSensFailRL_FA: nonqueued-sender-com-spec{data-element=Value, init-value=0}, provided-interface=VeSCMR_b_Lv2WhlSensFailRL_FA
      VeSCMR_n_Lv2WhlRL_Spd: nonqueued-sender-com-spec{data-element=Value, init-value=0}, provided-interface=VeSCMR_n_Lv2WhlRL_Spd
      VeSCMR_b_Lv2WhlRL_Spd_FA: nonqueued-sender-com-spec{data-element=Value, init-value=0}, provided-interface=VeSCMR_b_Lv2WhlRL_Spd_FA
      VeSCMR_e_Lv2WhlDirFR_Stat: nonqueued-sender-com-spec{data-element=Value, init-value=0}, provided-interface=VeSCMR_e_Lv2WhlDirFR_Stat
      VeSCMR_b_Lv2WhlDirFR_Stat_FA: nonqueued-sender-com-spec{data-element=Value, init-value=0}, provided-interface=VeSCMR_b_Lv2WhlDirFR_Stat_FA
      VeSCMR_b_Lv2WhlSensFailFR: nonqueued-sender-com-spec{data-element=Value, init-value=0}, provided-interface=VeSCMR_b_Lv2WhlSensFailFR
      VeSCMR_b_Lv2WhlSensFailFR_FA: nonqueued-sender-com-spec{data-element=Value, init-value=0}, provided-interface=VeSCMR_b_Lv2WhlSensFailFR_FA
      VeSCMR_n_Lv2WhlFR_Spd: nonqueued-sender-com-spec{data-element=Value, init-value=0}, provided-interface=VeSCMR_n_Lv2WhlFR_Spd
      VeSCMR_b_Lv2WhlFR_Spd_FA: nonqueued-sender-com-spec{data-element=Value, init-value=0}, provided-interface=VeSCMR_b_Lv2WhlFR_Spd_FA
      VeSCMR_e_Lv2WhlDirRR_Stat: nonqueued-sender-com-spec{data-element=Value, init-value=0}, provided-interface=VeSCMR_e_Lv2WhlDirRR_Stat
      VeSCMR_b_Lv2WhlDirRR_Stat_FA: nonqueued-sender-com-spec{data-element=Value, init-value=0}, provided-interface=VeSCMR_b_Lv2WhlDirRR_Stat_FA
      VeSCMR_b_Lv2WhlSensFailRR: nonqueued-sender-com-spec{data-element=Value, init-value=0}, provided-interface=VeSCMR_b_Lv2WhlSensFailRR
      VeSCMR_b_Lv2WhlSensFailRR_FA: nonqueued-sender-com-spec{data-element=Value, init-value=0}, provided-interface=VeSCMR_b_Lv2WhlSensFailRR_FA
      VeSCMR_n_Lv2WhlRR_Spd: nonqueued-sender-com-spec{data-element=Value, init-value=0}, provided-interface=VeSCMR_n_Lv2WhlRR_Spd
      VeSCMR_b_Lv2WhlRR_Spd_FA: nonqueued-sender-com-spec{data-element=Value, init-value=0}, provided-interface=VeSCMR_b_Lv2WhlRR_Spd_FA
      VeSCMR_b_Lv2ASRActive: nonqueued-sender-com-spec{data-element=Value, init-value=0}, provided-interface=VeSCMR_b_Lv2ASRActive
      VeSCMR_b_Lv2ASR_MSRActv_FA: nonqueued-sender-com-spec{data-element=Value, init-value=0}, provided-interface=VeSCMR_b_Lv2ASR_MSRActv_FA
      VeSCMR_e_Lv2EPB_HoldSts: nonqueued-sender-com-spec{data-element=Value, init-value=CeSTMR_e_EPBHoldSts_REL}, provided-interface=VeSCMR_e_Lv2EPB_HoldSts
      VeSCMR_b_Lv2EPB_HoldSts_FA: nonqueued-sender-com-spec{data-element=Value, init-value=0}, provided-interface=VeSCMR_b_Lv2EPB_HoldSts_FA
      VeSCMR_b_Lv2MSRActive: nonqueued-sender-com-spec{data-element=Value, init-value=0}, provided-interface=VeSCMR_b_Lv2MSRActive
      VeSCMR_b_Lv2ABSFailSts: nonqueued-sender-com-spec{data-element=Value, init-value=0}, provided-interface=VeSCMR_b_Lv2ABSFailSts
      VeSCMR_b_Lv2ABSFailSts_FA: nonqueued-sender-com-spec{data-element=Value, init-value=0}, provided-interface=VeSCMR_b_Lv2ABSFailSts_FA
      VeSCMR_b_Lv2ACC_Engaged: nonqueued-sender-com-spec{data-element=Value, init-value=0}, provided-interface=VeSCMR_b_Lv2ACC_Engaged
      VeSCMR_b_Lv2ACC_Engaged_FA: nonqueued-sender-com-spec{data-element=Value, init-value=0}, provided-interface=VeSCMR_b_Lv2ACC_Engaged_FA
      VeSCMR_b_Lv2ESC_FailSts: nonqueued-sender-com-spec{data-element=Value, init-value=0}, provided-interface=VeSCMR_b_Lv2ESC_FailSts
      VeSCMR_b_Lv2ESC_FailSts_FA: nonqueued-sender-com-spec{data-element=Value, init-value=0}, provided-interface=VeSCMR_b_Lv2ESC_FailSts_FA
      VeSCMR_b_Lv2Function2Sts: nonqueued-sender-com-spec{data-element=Value, init-value=0}, provided-interface=VeSCMR_b_Lv2Function2Sts
      VeSCMR_b_Lv2Function2Sts_FA: nonqueued-sender-com-spec{data-element=Value, init-value=0}, provided-interface=VeSCMR_b_Lv2Function2Sts_FA
      VeSCMR_b_Lv2RollsModeAct: nonqueued-sender-com-spec{data-element=Value, init-value=0}, provided-interface=VeSCMR_b_Lv2RollsModeAct
      VeSCMR_b_Lv2RollsModeAct_FA: nonqueued-sender-com-spec{data-element=Value, init-value=0}, provided-interface=VeSCMR_b_Lv2RollsModeAct_FA
      VeSCMR_b_Lv2FrntAxlMaxRq_BSM: nonqueued-sender-com-spec{data-element=Value, init-value=0}, provided-interface=VeSCMR_b_Lv2FrntAxlMaxRq_BSM
      VeSCMR_b_Lv2FrntAxlMaxRq_BSM_FA: nonqueued-sender-com-spec{data-element=Value, init-value=0}, provided-interface=VeSCMR_b_Lv2FrntAxlMaxRq_BSM_FA
      VeSCMR_b_Lv2FrntAxlMinRq_BSM: nonqueued-sender-com-spec{data-element=Value, init-value=0}, provided-interface=VeSCMR_b_Lv2FrntAxlMinRq_BSM
      VeSCMR_b_Lv2FrntAxlMinRq_BSM_FA: nonqueued-sender-com-spec{data-element=Value, init-value=0}, provided-interface=VeSCMR_b_Lv2FrntAxlMinRq_BSM_FA
      VeSCMR_M_Lv2FrntAxlRq_BSM: nonqueued-sender-com-spec{data-element=Value, init-value=0}, provided-interface=VeSCMR_M_Lv2FrntAxlRq_BSM
      VeSCMR_b_Lv2FrntAxlRq_BSM_FA: nonqueued-sender-com-spec{data-element=Value, init-value=0}, provided-interface=VeSCMR_b_Lv2FrntAxlRq_BSM_FA
      VeSCMR_b_Lv2RrAxlMaxRq_BSM: nonqueued-sender-com-spec{data-element=Value, init-value=0}, provided-interface=VeSCMR_b_Lv2RrAxlMaxRq_BSM
      VeSCMR_b_Lv2RrAxlMaxRq_BSM_FA: nonqueued-sender-com-spec{data-element=Value, init-value=0}, provided-interface=VeSCMR_b_Lv2RrAxlMaxRq_BSM_FA
      VeSCMR_b_Lv2RrAxlMinRq_BSM: nonqueued-sender-com-spec{data-element=Value, init-value=0}, provided-interface=VeSCMR_b_Lv2RrAxlMinRq_BSM
      VeSCMR_b_Lv2RrAxlMinRq_BSM_FA: nonqueued-sender-com-spec{data-element=Value, init-value=0}, provided-interface=VeSCMR_b_Lv2RrAxlMinRq_BSM_FA
      VeSCMR_M_Lv2RrAxlRq_BSM: nonqueued-sender-com-spec{data-element=Value, init-value=0}, provided-interface=VeSCMR_M_Lv2RrAxlRq_BSM
      VeSCMR_b_Lv2RrAxlRq_BSM_FA: nonqueued-sender-com-spec{data-element=Value, init-value=0}, provided-interface=VeSCMR_b_Lv2RrAxlRq_BSM_FA
      VeSCMR_M_Lv2RgnBrkAxTrqReq: nonqueued-sender-com-spec{data-element=Value, init-value=0}, provided-interface=VeSCMR_M_Lv2RgnBrkAxTrqReq
      VeSCMR_b_Lv2RgnBrkAxTrqReq_FA: nonqueued-sender-com-spec{data-element=Value, init-value=0}, provided-interface=VeSCMR_b_Lv2RgnBrkAxTrqReq_FA
      VeSCMR_Pct_Lv2BrkTravelSts: nonqueued-sender-com-spec{data-element=Value, init-value=0}, provided-interface=VeSCMR_Pct_Lv2BrkTravelSts
      VeSCMR_b_Lv2BrkTravelSts_FA: nonqueued-sender-com-spec{data-element=Value, init-value=0}, provided-interface=VeSCMR_b_Lv2BrkTravelSts_FA
      VeSCMR_b_Lv2BrkPdl_Flt: nonqueued-sender-com-spec{data-element=Value, init-value=0}, provided-interface=VeSCMR_b_Lv2BrkPdl_Flt
      VeSCMR_b_Lv2BrkPdl_Flt_FA: nonqueued-sender-com-spec{data-element=Value, init-value=0}, provided-interface=VeSCMR_b_Lv2BrkPdl_Flt_FA
      VeSCMR_e_Lv2BrkPdlStat: nonqueued-sender-com-spec{data-element=Value, init-value=0}, provided-interface=VeSCMR_e_Lv2BrkPdlStat
      VeSCMR_b_Lv2BrkPdlStat_FA: nonqueued-sender-com-spec{data-element=Value, init-value=0}, provided-interface=VeSCMR_b_Lv2BrkPdlStat_FA
      VeSCMR_e_Lv2ESS_EngStateEE: nonqueued-sender-com-spec{data-element=Value, init-value=0}, provided-interface=VeSCMR_e_Lv2ESS_EngStateEE
      VeSCMR_b_Lv2ESS_EngStateEE_FA: nonqueued-sender-com-spec{data-element=Value, init-value=0}, provided-interface=VeSCMR_b_Lv2ESS_EngStateEE_FA
      VeSCMR_b_Lv2SpeedUnit: nonqueued-sender-com-spec{data-element=Value, init-value=0}, provided-interface=VeSCMR_b_Lv2SpeedUnit
      VeSCMR_b_Lv2SpeedUnit_FA: nonqueued-sender-com-spec{data-element=Value, init-value=0}, provided-interface=VeSCMR_b_Lv2SpeedUnit_FA
      VeSCMR_e_Lv2GlobDrvMdRq: nonqueued-sender-com-spec{data-element=Value, init-value=0}, provided-interface=VeSCMR_e_Lv2GlobDrvMdRq
      VeSCMR_b_Lv2GlobDrvMdRq_FA: nonqueued-sender-com-spec{data-element=Value, init-value=0}, provided-interface=VeSCMR_b_Lv2GlobDrvMdRq_FA
      VeSR2B_y_APM_CtrlSts_Fbk_FD11: nonqueued-sender-com-spec{data-element=Value, init-value=0}, provided-interface=VeSR2B_y_APM_CtrlSts_Fbk_FD11
      VeSR2B_y_APM_CtrlSts_Fbk_FD11_SigSts: nonqueued-sender-com-spec{data-element=Value, init-value=0}, provided-interface=VeSR2B_y_APM_CtrlSts_Fbk_FD11_SigSts
      VeSR2B_y_APM_FailureReason_FD11: nonqueued-sender-com-spec{data-element=Value, init-value=0}, provided-interface=VeSR2B_y_APM_FailureReason_FD11
      VeSR2B_y_APM_FailureReason_FD11_SigSts: nonqueued-sender-com-spec{data-element=Value, init-value=0}, provided-interface=VeSR2B_y_APM_FailureReason_FD11_SigSts
      VeSR2B_y_APM_FailureType_FD11: nonqueued-sender-com-spec{data-element=Value, init-value=0}, provided-interface=VeSR2B_y_APM_FailureType_FD11
      VeSR2B_y_APM_FailureType_FD11_SigSts: nonqueued-sender-com-spec{data-element=Value, init-value=0}, provided-interface=VeSR2B_y_APM_FailureType_FD11_SigSts
      VeSR2B_U_APM_HV_V_Fbk_FD11: nonqueued-sender-com-spec{data-element=Value, init-value=0}, provided-interface=VeSR2B_U_APM_HV_V_Fbk_FD11
      VeSR2B_y_APM_HV_V_Fbk_FD11_SigSts: nonqueued-sender-com-spec{data-element=Value, init-value=0}, provided-interface=VeSR2B_y_APM_HV_V_Fbk_FD11_SigSts
      VeSR2B_U_APM_LV_V_Fbk_FD11: nonqueued-sender-com-spec{data-element=Value, init-value=0}, provided-interface=VeSR2B_U_APM_LV_V_Fbk_FD11
      VeSR2B_y_APM_LV_V_Fbk_FD11_SigSts: nonqueued-sender-com-spec{data-element=Value, init-value=0}, provided-interface=VeSR2B_y_APM_LV_V_Fbk_FD11_SigSts
      VeSR2B_b_BPCMCntctrsMTOWrn_FD11: nonqueued-sender-com-spec{data-element=Value, init-value=0}, provided-interface=VeSR2B_b_BPCMCntctrsMTOWrn_FD11
      VeSR2B_y_BPCMCntctrsMTOWrn_FD11_SigSts: nonqueued-sender-com-spec{data-element=Value, init-value=0}, provided-interface=VeSR2B_y_BPCMCntctrsMTOWrn_FD11_SigSts
      VeSR2B_b_BPCMCntctrsSTOWrn_FD11: nonqueued-sender-com-spec{data-element=Value, init-value=0}, provided-interface=VeSR2B_b_BPCMCntctrsSTOWrn_FD11
      VeSR2B_y_BPCMCntctrsSTOWrn_FD11_SigSts: nonqueued-sender-com-spec{data-element=Value, init-value=0}, provided-interface=VeSR2B_y_BPCMCntctrsSTOWrn_FD11_SigSts
      VeSR2B_I_BPCM_HV_Current_FD11: nonqueued-sender-com-spec{data-element=Value, init-value=0}, provided-interface=VeSR2B_I_BPCM_HV_Current_FD11
      VeSR2B_y_BPCM_HV_Current_FD11_SigSts: nonqueued-sender-com-spec{data-element=Value, init-value=0}, provided-interface=VeSR2B_y_BPCM_HV_Current_FD11_SigSts
      VeSR2B_U_BPCM_HV_IntVolt_FD11: nonqueued-sender-com-spec{data-element=Value, init-value=0}, provided-interface=VeSR2B_U_BPCM_HV_IntVolt_FD11
      VeSR2B_y_BPCM_HV_IntVolt_FD11_SigSts: nonqueued-sender-com-spec{data-element=Value, init-value=0}, provided-interface=VeSR2B_y_BPCM_HV_IntVolt_FD11_SigSts
      VeSR2B_Pct_BPCM_HV_SOC_FD11: nonqueued-sender-com-spec{data-element=Value, init-value=0}, provided-interface=VeSR2B_Pct_BPCM_HV_SOC_FD11
      VeSR2B_y_BPCM_HV_SOC_FD11_SigSts: nonqueued-sender-com-spec{data-element=Value, init-value=0}, provided-interface=VeSR2B_y_BPCM_HV_SOC_FD11_SigSts
      VeSR2B_T_BPCM_HV_Temp_Max_FD11: nonqueued-sender-com-spec{data-element=Value, init-value=0}, provided-interface=VeSR2B_T_BPCM_HV_Temp_Max_FD11
      VeSR2B_y_BPCM_HV_Temp_Max_FD11_SigSts: nonqueued-sender-com-spec{data-element=Value, init-value=0}, provided-interface=VeSR2B_y_BPCM_HV_Temp_Max_FD11_SigSts
      VeSR2B_T_BPCM_HV_Temp_Min_FD11: nonqueued-sender-com-spec{data-element=Value, init-value=0}, provided-interface=VeSR2B_T_BPCM_HV_Temp_Min_FD11
      VeSR2B_y_BPCM_HV_Temp_Min_FD11_SigSts: nonqueued-sender-com-spec{data-element=Value, init-value=0}, provided-interface=VeSR2B_y_BPCM_HV_Temp_Min_FD11_SigSts
      VeSR2B_y_BPCM_HV_TracBusStsFD11: nonqueued-sender-com-spec{data-element=Value, init-value=0}, provided-interface=VeSR2B_y_BPCM_HV_TracBusStsFD11
      VeSR2B_y_BPCM_HV_TracBusStsFD11_SigSts: nonqueued-sender-com-spec{data-element=Value, init-value=0}, provided-interface=VeSR2B_y_BPCM_HV_TracBusStsFD11_SigSts
      VeSR2B_y_ProximitySts_FD11: nonqueued-sender-com-spec{data-element=Value, init-value=0}, provided-interface=VeSR2B_y_ProximitySts_FD11
      VeSR2B_y_ProximitySts_FD11_SigSts: nonqueued-sender-com-spec{data-element=Value, init-value=0}, provided-interface=VeSR2B_y_ProximitySts_FD11_SigSts
      VeSCMR_e_Lv2ACC_SystemSts: nonqueued-sender-com-spec{data-element=Value, init-value=CeSTMR_e_Off_M182}, provided-interface=VeSCMR_e_Lv2ACC_SystemSts
      VeSCMR_b_Lv2ACC_SystemSts_FA: nonqueued-sender-com-spec{data-element=Value, init-value=0}, provided-interface=VeSCMR_b_Lv2ACC_SystemSts_FA
      VeSCMR_M_Lv2ACC_WhlTrq_ADAS: nonqueued-sender-com-spec{data-element=Value, init-value=0}, provided-interface=VeSCMR_M_Lv2ACC_WhlTrq_ADAS
      VeSCMR_b_Lv2ACC_WhlTrq_ADAS_FA: nonqueued-sender-com-spec{data-element=Value, init-value=0}, provided-interface=VeSCMR_b_Lv2ACC_WhlTrq_ADAS_FA
      VeSCMR_b_Lv2ACC_WhlTrqEnbld: nonqueued-sender-com-spec{data-element=Value, init-value=0}, provided-interface=VeSCMR_b_Lv2ACC_WhlTrqEnbld
      VeSCMR_b_Lv2ACC_WhlTrqEnbld_FA: nonqueued-sender-com-spec{data-element=Value, init-value=0}, provided-interface=VeSCMR_b_Lv2ACC_WhlTrqEnbld_FA
      VeSCMR_M_Lv2BrkTrqCANC2: nonqueued-sender-com-spec{data-element=Value, init-value=0}, provided-interface=VeSCMR_M_Lv2BrkTrqCANC2
      VeSCMR_b_Lv2BrkTrqCANC2_FA: nonqueued-sender-com-spec{data-element=Value, init-value=0}, provided-interface=VeSCMR_b_Lv2BrkTrqCANC2_FA
      VeSCMR_M_Lv2BrkTrqDriverCANC2: nonqueued-sender-com-spec{data-element=Value, init-value=0}, provided-interface=VeSCMR_M_Lv2BrkTrqDriverCANC2
      VeSCMR_b_Lv2BrkTrqDriverCANC2_FA: nonqueued-sender-com-spec{data-element=Value, init-value=0}, provided-interface=VeSCMR_b_Lv2BrkTrqDriverCANC2_FA
      VeSCMR_p_Lv2BrakeBoostPressureCANC2: nonqueued-sender-com-spec{data-element=Value, init-value=0}, provided-interface=VeSCMR_p_Lv2BrakeBoostPressureCANC2
      VeSCMR_b_Lv2BrkBoostPressureCANC2_FA: nonqueued-sender-com-spec{data-element=Value, init-value=0}, provided-interface=VeSCMR_b_Lv2BrkBoostPressureCANC2_FA
      VeSCMR_e_Lv2Brk_Stat: nonqueued-sender-com-spec{data-element=Value, init-value=0}, provided-interface=VeSCMR_e_Lv2Brk_Stat
      VeSCMR_b_Lv2Brk_Stat_FA: nonqueued-sender-com-spec{data-element=Value, init-value=0}, provided-interface=VeSCMR_b_Lv2Brk_Stat_FA
      VeSCMR_v_Lv2VehSpdCANC2: nonqueued-sender-com-spec{data-element=Value, init-value=0}, provided-interface=VeSCMR_v_Lv2VehSpdCANC2
      VeSCMR_b_Lv2VehSpdCANC2_FA: nonqueued-sender-com-spec{data-element=Value, init-value=0}, provided-interface=VeSCMR_b_Lv2VehSpdCANC2_FA
      VeSCMR_n_Lv2WhlFL_RPS_CANC2: nonqueued-sender-com-spec{data-element=Value, init-value=0}, provided-interface=VeSCMR_n_Lv2WhlFL_RPS_CANC2
      VeSCMR_b_Lv2WhlFL_RPS_CANC2_FA: nonqueued-sender-com-spec{data-element=Value, init-value=0}, provided-interface=VeSCMR_b_Lv2WhlFL_RPS_CANC2_FA
      VeSCMR_n_Lv2WhlFR_RPS_CANC2: nonqueued-sender-com-spec{data-element=Value, init-value=0}, provided-interface=VeSCMR_n_Lv2WhlFR_RPS_CANC2
      VeSCMR_b_Lv2WhlFR_RPS_CANC2_FA: nonqueued-sender-com-spec{data-element=Value, init-value=0}, provided-interface=VeSCMR_b_Lv2WhlFR_RPS_CANC2_FA
      VeSCMR_M_Lv2ACC_WhlTrq: nonqueued-sender-com-spec{data-element=Value, init-value=0}, provided-interface=VeSCMR_M_Lv2ACC_WhlTrq
      VeSCMR_b_Lv2ACC_WhlTrq_FA: nonqueued-sender-com-spec{data-element=Value, init-value=0}, provided-interface=VeSCMR_b_Lv2ACC_WhlTrq_FA
      VeSCMR_b_Lv2FrntAxlMaxRqCANC2_BSM: nonqueued-sender-com-spec{data-element=Value, init-value=0}, provided-interface=VeSCMR_b_Lv2FrntAxlMaxRqCANC2_BSM
      VeSCMR_b_Lv2FrntAxlMaxRqCANC2_BSM_FA: nonqueued-sender-com-spec{data-element=Value, init-value=0}, provided-interface=VeSCMR_b_Lv2FrntAxlMaxRqCANC2_BSM_FA
      VeSCMR_b_Lv2FrntAxlMinRqCANC2_BSM: nonqueued-sender-com-spec{data-element=Value, init-value=0}, provided-interface=VeSCMR_b_Lv2FrntAxlMinRqCANC2_BSM
      VeSCMR_b_Lv2FrntAxlMinRqCANC2_BSM_FA: nonqueued-sender-com-spec{data-element=Value, init-value=0}, provided-interface=VeSCMR_b_Lv2FrntAxlMinRqCANC2_BSM_FA
      VeSCMR_M_Lv2FrntAxlRqCANC2_BSM: nonqueued-sender-com-spec{data-element=Value, init-value=0}, provided-interface=VeSCMR_M_Lv2FrntAxlRqCANC2_BSM
      VeSCMR_b_Lv2FrntAxlRqCANC2_BSM_FA: nonqueued-sender-com-spec{data-element=Value, init-value=0}, provided-interface=VeSCMR_b_Lv2FrntAxlRqCANC2_BSM_FA
      VeSCMR_b_Lv2RrAxlMaxRqCANC2_BSM: nonqueued-sender-com-spec{data-element=Value, init-value=0}, provided-interface=VeSCMR_b_Lv2RrAxlMaxRqCANC2_BSM
      VeSCMR_b_Lv2RrAxlMaxRqCANC2_BSM_FA: nonqueued-sender-com-spec{data-element=Value, init-value=0}, provided-interface=VeSCMR_b_Lv2RrAxlMaxRqCANC2_BSM_FA
      VeSCMR_b_Lv2RrAxlMinRqCANC2_BSM: nonqueued-sender-com-spec{data-element=Value, init-value=0}, provided-interface=VeSCMR_b_Lv2RrAxlMinRqCANC2_BSM
      VeSCMR_b_Lv2RrAxlMinRqCANC2_BSM_FA: nonqueued-sender-com-spec{data-element=Value, init-value=0}, provided-interface=VeSCMR_b_Lv2RrAxlMinRqCANC2_BSM_FA
      VeSCMR_M_Lv2RrAxlRqCANC2_BSM: nonqueued-sender-com-spec{data-element=Value, init-value=0}, provided-interface=VeSCMR_M_Lv2RrAxlRqCANC2_BSM
      VeSCMR_b_Lv2RrAxlRqCANC2_BSM_FA: nonqueued-sender-com-spec{data-element=Value, init-value=0}, provided-interface=VeSCMR_b_Lv2RrAxlRqCANC2_BSM_FA
      VeSCMR_Pct_Lv2BrkTravelStsCANC2: nonqueued-sender-com-spec{data-element=Value, init-value=0}, provided-interface=VeSCMR_Pct_Lv2BrkTravelStsCANC2
      VeSCMR_b_Lv2BrkTravelStsCANC2_FA: nonqueued-sender-com-spec{data-element=Value, init-value=0}, provided-interface=VeSCMR_b_Lv2BrkTravelStsCANC2_FA
      VeSCMR_e_Lv2BrkPdlStatCANC2: nonqueued-sender-com-spec{data-element=Value, init-value=0}, provided-interface=VeSCMR_e_Lv2BrkPdlStatCANC2
      VeSCMR_b_Lv2BrkPdlStatCANC2_FA: nonqueued-sender-com-spec{data-element=Value, init-value=0}, provided-interface=VeSCMR_b_Lv2BrkPdlStatCANC2_FA
      VeSCMR_phi_Lv2LwsAngle: nonqueued-sender-com-spec{data-element=Value, init-value=0}, provided-interface=VeSCMR_phi_Lv2LwsAngle
      VeSCMR_b_Lv2LwsAngle_FA: nonqueued-sender-com-spec{data-element=Value, init-value=0}, provided-interface=VeSCMR_b_Lv2LwsAngle_FA
      VeSCMR_a_Lv2LatAcceleration: nonqueued-sender-com-spec{data-element=Value, init-value=0}, provided-interface=VeSCMR_a_Lv2LatAcceleration
      VeSCMR_b_Lv2LatAcceleration_FA: nonqueued-sender-com-spec{data-element=Value, init-value=0}, provided-interface=VeSCMR_b_Lv2LatAcceleration_FA
      VeSCMR_b_Lv2LatAccelerationFailSts: nonqueued-sender-com-spec{data-element=Value, init-value=0}, provided-interface=VeSCMR_b_Lv2LatAccelerationFailSts
      VeSCMR_b_Lv2LatAccelerationFailSts_FA: nonqueued-sender-com-spec{data-element=Value, init-value=0}, provided-interface=VeSCMR_b_Lv2LatAccelerationFailSts_FA
      VeSCMR_a_Lv2LongAcceleration: nonqueued-sender-com-spec{data-element=Value, init-value=0}, provided-interface=VeSCMR_a_Lv2LongAcceleration
      VeSCMR_b_Lv2LongAcceleration_FA: nonqueued-sender-com-spec{data-element=Value, init-value=0}, provided-interface=VeSCMR_b_Lv2LongAcceleration_FA
      VeSCMR_b_Lv2LongAccelerationFailSts: nonqueued-sender-com-spec{data-element=Value, init-value=0}, provided-interface=VeSCMR_b_Lv2LongAccelerationFailSts
      VeSCMR_b_Lv2LongAccelerationFailSts_FA: nonqueued-sender-com-spec{data-element=Value, init-value=0}, provided-interface=VeSCMR_b_Lv2LongAccelerationFailSts_FA
      VeSCMR_dphi_Lv2YawRate: nonqueued-sender-com-spec{data-element=Value, init-value=0}, provided-interface=VeSCMR_dphi_Lv2YawRate
      VeSCMR_b_Lv2YawRate_FA: nonqueued-sender-com-spec{data-element=Value, init-value=0}, provided-interface=VeSCMR_b_Lv2YawRate_FA
      VeSCMR_b_Lv2YawRateFailSts: nonqueued-sender-com-spec{data-element=Value, init-value=0}, provided-interface=VeSCMR_b_Lv2YawRateFailSts
      VeSCMR_b_Lv2YawRateFailSts_FA: nonqueued-sender-com-spec{data-element=Value, init-value=0}, provided-interface=VeSCMR_b_Lv2YawRateFailSts_FA
      VeSCMR_b_Lv2ScndryPRNDDispFailSts: nonqueued-sender-com-spec{data-element=Value, init-value=0}, provided-interface=VeSCMR_b_Lv2ScndryPRNDDispFailSts
      VeSCMR_b_Lv2ScndryPRNDDispFailSts_FA: nonqueued-sender-com-spec{data-element=Value, init-value=0}, provided-interface=VeSCMR_b_Lv2ScndryPRNDDispFailSts_FA
      VeSCMR_b_Lv2Scndry_PRNDFailSts: nonqueued-sender-com-spec{data-element=Value, init-value=0}, provided-interface=VeSCMR_b_Lv2Scndry_PRNDFailSts
      VeSCMR_b_Lv2Scndry_PRNDFailSts_FA: nonqueued-sender-com-spec{data-element=Value, init-value=0}, provided-interface=VeSCMR_b_Lv2Scndry_PRNDFailSts_FA
      VeSCMR_e_Lv2DrvRqShftROT_Scndry: nonqueued-sender-com-spec{data-element=Value, init-value=CeGSMR_e_PRNDInit}, provided-interface=VeSCMR_e_Lv2DrvRqShftROT_Scndry
      VeSCMR_b_Lv2DrvRqShftROT_Scndry_FA: nonqueued-sender-com-spec{data-element=Value, init-value=0}, provided-interface=VeSCMR_b_Lv2DrvRqShftROT_Scndry_FA
      VeSCMR_y_Lv2GearShiftType: nonqueued-sender-com-spec{data-element=Value, init-value=0}, provided-interface=VeSCMR_y_Lv2GearShiftType
      VeSCMR_b_Lv2GearShiftType_FA: nonqueued-sender-com-spec{data-element=Value, init-value=0}, provided-interface=VeSCMR_b_Lv2GearShiftType_FA
      VeSCMR_y_Lv2MRGB_Current_Gr: nonqueued-sender-com-spec{data-element=Value, init-value=0}, provided-interface=VeSCMR_y_Lv2MRGB_Current_Gr
      VeSCMR_b_Lv2MRGB_Current_Gr_FA: nonqueued-sender-com-spec{data-element=Value, init-value=0}, provided-interface=VeSCMR_b_Lv2MRGB_Current_Gr_FA
      VeSCMR_y_Lv2MRGB_Target_Gr: nonqueued-sender-com-spec{data-element=Value, init-value=0}, provided-interface=VeSCMR_y_Lv2MRGB_Target_Gr
      VeSCMR_b_Lv2MRGB_Target_Gr_FA: nonqueued-sender-com-spec{data-element=Value, init-value=0}, provided-interface=VeSCMR_b_Lv2MRGB_Target_Gr_FA
      VeSCMR_M_Lv2RrLkTrq: nonqueued-sender-com-spec{data-element=Value, init-value=0}, provided-interface=VeSCMR_M_Lv2RrLkTrq
      VeSCMR_b_Lv2RrLkTrq_FA: nonqueued-sender-com-spec{data-element=Value, init-value=0}, provided-interface=VeSCMR_b_Lv2RrLkTrq_FA
      VeSCMR_e_Lv2RrSysStat: nonqueued-sender-com-spec{data-element=Value, init-value=0}, provided-interface=VeSCMR_e_Lv2RrSysStat
      VeSCMR_b_Lv2RrSysStat_FA: nonqueued-sender-com-spec{data-element=Value, init-value=0}, provided-interface=VeSCMR_b_Lv2RrSysStat_FA
      VeSCMR_T_Lv2RrTemp_Avl: nonqueued-sender-com-spec{data-element=Value, init-value=0}, provided-interface=VeSCMR_T_Lv2RrTemp_Avl
      VeSCMR_b_Lv2RrTemp_Avl_FA: nonqueued-sender-com-spec{data-element=Value, init-value=0}, provided-interface=VeSCMR_b_Lv2RrTemp_Avl_FA
      VeSCMR_r_Lv2TransTrqRatio: nonqueued-sender-com-spec{data-element=Value, init-value=0}, provided-interface=VeSCMR_r_Lv2TransTrqRatio
      VeSCMR_b_Lv2TransTrqRatio_FA: nonqueued-sender-com-spec{data-element=Value, init-value=0}, provided-interface=VeSCMR_b_Lv2TransTrqRatio_FA
      VeSR2B_b_MCPA_HV_CnctrOpn_Req_P_FD16: nonqueued-sender-com-spec{data-element=Value, init-value=0}, provided-interface=VeSR2B_b_MCPA_HV_CnctrOpn_Req_P_FD16
      VeSR2B_y_MCPA_HV_CnctrOpn_Req_P_FD16_SigSts: nonqueued-sender-com-spec{data-element=Value, init-value=0}, provided-interface=VeSR2B_y_MCPA_HV_CnctrOpn_Req_P_FD16_SigSts
      VeSR2B_M_MCPA_MaxTorq_P_FD16: nonqueued-sender-com-spec{data-element=Value, init-value=0}, provided-interface=VeSR2B_M_MCPA_MaxTorq_P_FD16
      VeSR2B_y_MCPA_MaxTorq_P_FD16_SigSts: nonqueued-sender-com-spec{data-element=Value, init-value=0}, provided-interface=VeSR2B_y_MCPA_MaxTorq_P_FD16_SigSts
      VeSR2B_M_MCPA_MinTorq_P_FD16: nonqueued-sender-com-spec{data-element=Value, init-value=0}, provided-interface=VeSR2B_M_MCPA_MinTorq_P_FD16
      VeSR2B_y_MCPA_MinTorq_P_FD16_SigSts: nonqueued-sender-com-spec{data-element=Value, init-value=0}, provided-interface=VeSR2B_y_MCPA_MinTorq_P_FD16_SigSts
      VeSR2B_n_MCPA_RPM_P_FD16: nonqueued-sender-com-spec{data-element=Value, init-value=0}, provided-interface=VeSR2B_n_MCPA_RPM_P_FD16
      VeSR2B_y_MCPA_RPM_P_FD16_SigSts: nonqueued-sender-com-spec{data-element=Value, init-value=0}, provided-interface=VeSR2B_y_MCPA_RPM_P_FD16_SigSts
      VeSR2B_b_MCPA_RPM_V_P_FD16: nonqueued-sender-com-spec{data-element=Value, init-value=0}, provided-interface=VeSR2B_b_MCPA_RPM_V_P_FD16
      VeSR2B_y_MCPA_RPM_V_P_FD16_SigSts: nonqueued-sender-com-spec{data-element=Value, init-value=0}, provided-interface=VeSR2B_y_MCPA_RPM_V_P_FD16_SigSts
      VeSR2B_T_MCPA_Temp_P_FD16: nonqueued-sender-com-spec{data-element=Value, init-value=0}, provided-interface=VeSR2B_T_MCPA_Temp_P_FD16
      VeSR2B_y_MCPA_Temp_P_FD16_SigSts: nonqueued-sender-com-spec{data-element=Value, init-value=0}, provided-interface=VeSR2B_y_MCPA_Temp_P_FD16_SigSts
      VeSR2B_M_MCPA_TorqAchved_AEMD_P_FD16: nonqueued-sender-com-spec{data-element=Value, init-value=0}, provided-interface=VeSR2B_M_MCPA_TorqAchved_AEMD_P_FD16
      VeSR2B_y_MCPA_TorqAchved_AEMD_P_FD16_SigSts: nonqueued-sender-com-spec{data-element=Value, init-value=0}, provided-interface=VeSR2B_y_MCPA_TorqAchved_AEMD_P_FD16_SigSts
      VeSR2B_b_MCPA_TrqAchvd_AEMD_V_P_FD16: nonqueued-sender-com-spec{data-element=Value, init-value=0}, provided-interface=VeSR2B_b_MCPA_TrqAchvd_AEMD_V_P_FD16
      VeSR2B_y_MCPA_TrqAchvd_AEMD_V_P_FD16_SigSts: nonqueued-sender-com-spec{data-element=Value, init-value=0}, provided-interface=VeSR2B_y_MCPA_TrqAchvd_AEMD_V_P_FD16_SigSts
      VeSR2B_M_MCPA_Torque_Achieved_P_FD16: nonqueued-sender-com-spec{data-element=Value, init-value=0}, provided-interface=VeSR2B_M_MCPA_Torque_Achieved_P_FD16
      VeSR2B_y_MCPA_Torque_Achieved_P_FD16_SigSts: nonqueued-sender-com-spec{data-element=Value, init-value=0}, provided-interface=VeSR2B_y_MCPA_Torque_Achieved_P_FD16_SigSts
      VeSR2B_b_MCPA_Torque_Achved_V_P_FD16: nonqueued-sender-com-spec{data-element=Value, init-value=0}, provided-interface=VeSR2B_b_MCPA_Torque_Achved_V_P_FD16
      VeSR2B_y_MCPA_Torque_Achved_V_P_FD16_SigSts: nonqueued-sender-com-spec{data-element=Value, init-value=0}, provided-interface=VeSR2B_y_MCPA_Torque_Achved_V_P_FD16_SigSts
      VeSR2B_b_MCPB_HV_CnctrOpn_Req_P_FD16: nonqueued-sender-com-spec{data-element=Value, init-value=0}, provided-interface=VeSR2B_b_MCPB_HV_CnctrOpn_Req_P_FD16
      VeSR2B_y_MCPB_HV_CnctrOpn_Req_P_FD16_SigSts: nonqueued-sender-com-spec{data-element=Value, init-value=0}, provided-interface=VeSR2B_y_MCPB_HV_CnctrOpn_Req_P_FD16_SigSts
      VeSR2B_M_MCPB_MaxTorq_P_FD16: nonqueued-sender-com-spec{data-element=Value, init-value=0}, provided-interface=VeSR2B_M_MCPB_MaxTorq_P_FD16
      VeSR2B_y_MCPB_MaxTorq_P_FD16_SigSts: nonqueued-sender-com-spec{data-element=Value, init-value=0}, provided-interface=VeSR2B_y_MCPB_MaxTorq_P_FD16_SigSts
      VeSR2B_M_MCPB_MinTorq_P_FD16: nonqueued-sender-com-spec{data-element=Value, init-value=0}, provided-interface=VeSR2B_M_MCPB_MinTorq_P_FD16
      VeSR2B_y_MCPB_MinTorq_P_FD16_SigSts: nonqueued-sender-com-spec{data-element=Value, init-value=0}, provided-interface=VeSR2B_y_MCPB_MinTorq_P_FD16_SigSts
      VeSR2B_y_MCPB_MtrIndex_P_FD16: nonqueued-sender-com-spec{data-element=Value, init-value=0}, provided-interface=VeSR2B_y_MCPB_MtrIndex_P_FD16
      VeSR2B_y_MCPB_MtrIndex_P_FD16_SigSts: nonqueued-sender-com-spec{data-element=Value, init-value=0}, provided-interface=VeSR2B_y_MCPB_MtrIndex_P_FD16_SigSts
      VeSR2B_n_MCPB_RPM_P_FD16: nonqueued-sender-com-spec{data-element=Value, init-value=0}, provided-interface=VeSR2B_n_MCPB_RPM_P_FD16
      VeSR2B_y_MCPB_RPM_P_FD16_SigSts: nonqueued-sender-com-spec{data-element=Value, init-value=0}, provided-interface=VeSR2B_y_MCPB_RPM_P_FD16_SigSts
      VeSR2B_b_MCPB_RPM_V_P_FD16: nonqueued-sender-com-spec{data-element=Value, init-value=0}, provided-interface=VeSR2B_b_MCPB_RPM_V_P_FD16
      VeSR2B_y_MCPB_RPM_V_P_FD16_SigSts: nonqueued-sender-com-spec{data-element=Value, init-value=0}, provided-interface=VeSR2B_y_MCPB_RPM_V_P_FD16_SigSts
      VeSR2B_y_MCPB_Temp_P_FD16: nonqueued-sender-com-spec{data-element=Value, init-value=0}, provided-interface=VeSR2B_y_MCPB_Temp_P_FD16
      VeSR2B_y_MCPB_Temp_P_FD16_SigSts: nonqueued-sender-com-spec{data-element=Value, init-value=0}, provided-interface=VeSR2B_y_MCPB_Temp_P_FD16_SigSts
      VeSR2B_M_MCPB_TorqAchved_AEMD_P_FD16: nonqueued-sender-com-spec{data-element=Value, init-value=0}, provided-interface=VeSR2B_M_MCPB_TorqAchved_AEMD_P_FD16
      VeSR2B_y_MCPB_TorqAchved_AEMD_P_FD16_SigSts: nonqueued-sender-com-spec{data-element=Value, init-value=0}, provided-interface=VeSR2B_y_MCPB_TorqAchved_AEMD_P_FD16_SigSts
      VeSR2B_b_MCPB_TrqAchvd_AEMD_V_P_FD16: nonqueued-sender-com-spec{data-element=Value, init-value=0}, provided-interface=VeSR2B_b_MCPB_TrqAchvd_AEMD_V_P_FD16
      VeSR2B_y_MCPB_TrqAchvd_AEMD_V_P_FD16_SigSts: nonqueued-sender-com-spec{data-element=Value, init-value=0}, provided-interface=VeSR2B_y_MCPB_TrqAchvd_AEMD_V_P_FD16_SigSts
      VeSR2B_M_MCPB_Torque_Achieved_P_FD16: nonqueued-sender-com-spec{data-element=Value, init-value=0}, provided-interface=VeSR2B_M_MCPB_Torque_Achieved_P_FD16
      VeSR2B_y_MCPB_Torque_Achieved_P_FD16_SigSts: nonqueued-sender-com-spec{data-element=Value, init-value=0}, provided-interface=VeSR2B_y_MCPB_Torque_Achieved_P_FD16_SigSts
      VeSR2B_b_MCPB_Torque_Achved_V_P_FD16: nonqueued-sender-com-spec{data-element=Value, init-value=0}, provided-interface=VeSR2B_b_MCPB_Torque_Achved_V_P_FD16
      VeSR2B_y_MCPB_Torque_Achved_V_P_FD16_SigSts: nonqueued-sender-com-spec{data-element=Value, init-value=0}, provided-interface=VeSR2B_y_MCPB_Torque_Achved_V_P_FD16_SigSts
      VeSR2B_y_APM_CtrlSts_Fbk_FD5: nonqueued-sender-com-spec{data-element=Value, init-value=0}, provided-interface=VeSR2B_y_APM_CtrlSts_Fbk_FD5
      VeSR2B_y_APM_CtrlSts_Fbk_FD5_SigSts: nonqueued-sender-com-spec{data-element=Value, init-value=0}, provided-interface=VeSR2B_y_APM_CtrlSts_Fbk_FD5_SigSts
      VeSR2B_y_APM_FailureReason_FD5: nonqueued-sender-com-spec{data-element=Value, init-value=0}, provided-interface=VeSR2B_y_APM_FailureReason_FD5
      VeSR2B_y_APM_FailureReason_FD5_SigSts: nonqueued-sender-com-spec{data-element=Value, init-value=0}, provided-interface=VeSR2B_y_APM_FailureReason_FD5_SigSts
      VeSR2B_y_APM_FailureType_FD5: nonqueued-sender-com-spec{data-element=Value, init-value=0}, provided-interface=VeSR2B_y_APM_FailureType_FD5
      VeSR2B_y_APM_FailureType_FD5_SigSts: nonqueued-sender-com-spec{data-element=Value, init-value=0}, provided-interface=VeSR2B_y_APM_FailureType_FD5_SigSts
      VeSR2B_U_APM_HV_V_Fbk_FD5: nonqueued-sender-com-spec{data-element=Value, init-value=0}, provided-interface=VeSR2B_U_APM_HV_V_Fbk_FD5
      VeSR2B_y_APM_HV_V_Fbk_FD5_SigSts: nonqueued-sender-com-spec{data-element=Value, init-value=0}, provided-interface=VeSR2B_y_APM_HV_V_Fbk_FD5_SigSts
      VeSR2B_U_APM_LV_V_Fbk_FD5: nonqueued-sender-com-spec{data-element=Value, init-value=0}, provided-interface=VeSR2B_U_APM_LV_V_Fbk_FD5
      VeSR2B_y_APM_LV_V_Fbk_FD5_SigSts: nonqueued-sender-com-spec{data-element=Value, init-value=0}, provided-interface=VeSR2B_y_APM_LV_V_Fbk_FD5_SigSts
      VeSR2B_b_BPCMCntctrsMTOWrn_FD5: nonqueued-sender-com-spec{data-element=Value, init-value=0}, provided-interface=VeSR2B_b_BPCMCntctrsMTOWrn_FD5
      VeSR2B_y_BPCMCntctrsMTOWrn_FD5_SigSts: nonqueued-sender-com-spec{data-element=Value, init-value=0}, provided-interface=VeSR2B_y_BPCMCntctrsMTOWrn_FD5_SigSts
      VeSR2B_b_BPCMCntctrsSTOWrn_FD5: nonqueued-sender-com-spec{data-element=Value, init-value=0}, provided-interface=VeSR2B_b_BPCMCntctrsSTOWrn_FD5
      VeSR2B_y_BPCMCntctrsSTOWrn_FD5_SigSts: nonqueued-sender-com-spec{data-element=Value, init-value=0}, provided-interface=VeSR2B_y_BPCMCntctrsSTOWrn_FD5_SigSts
      VeSR2B_I_BPCM_HV_Current_FD5: nonqueued-sender-com-spec{data-element=Value, init-value=0}, provided-interface=VeSR2B_I_BPCM_HV_Current_FD5
      VeSR2B_y_BPCM_HV_Current_FD5_SigSts: nonqueued-sender-com-spec{data-element=Value, init-value=0}, provided-interface=VeSR2B_y_BPCM_HV_Current_FD5_SigSts
      VeSR2B_U_BPCM_HV_IntVolt_FD5: nonqueued-sender-com-spec{data-element=Value, init-value=0}, provided-interface=VeSR2B_U_BPCM_HV_IntVolt_FD5
      VeSR2B_y_BPCM_HV_IntVolt_FD5_SigSts: nonqueued-sender-com-spec{data-element=Value, init-value=0}, provided-interface=VeSR2B_y_BPCM_HV_IntVolt_FD5_SigSts
      VeSR2B_Pct_BPCM_HV_SOC_FD5: nonqueued-sender-com-spec{data-element=Value, init-value=0}, provided-interface=VeSR2B_Pct_BPCM_HV_SOC_FD5
      VeSR2B_y_BPCM_HV_SOC_FD5_SigSts: nonqueued-sender-com-spec{data-element=Value, init-value=0}, provided-interface=VeSR2B_y_BPCM_HV_SOC_FD5_SigSts
      VeSR2B_T_BPCM_HV_Temp_Max_FD5: nonqueued-sender-com-spec{data-element=Value, init-value=0}, provided-interface=VeSR2B_T_BPCM_HV_Temp_Max_FD5
      VeSR2B_y_BPCM_HV_Temp_Max_FD5_SigSts: nonqueued-sender-com-spec{data-element=Value, init-value=0}, provided-interface=VeSR2B_y_BPCM_HV_Temp_Max_FD5_SigSts
      VeSR2B_T_BPCM_HV_Temp_Min_FD5: nonqueued-sender-com-spec{data-element=Value, init-value=0}, provided-interface=VeSR2B_T_BPCM_HV_Temp_Min_FD5
      VeSR2B_y_BPCM_HV_Temp_Min_FD5_SigSts: nonqueued-sender-com-spec{data-element=Value, init-value=0}, provided-interface=VeSR2B_y_BPCM_HV_Temp_Min_FD5_SigSts
      VeSR2B_y_BPCM_HV_TracBusStsFD5: nonqueued-sender-com-spec{data-element=Value, init-value=0}, provided-interface=VeSR2B_y_BPCM_HV_TracBusStsFD5
      VeSR2B_y_BPCM_HV_TracBusStsFD5_SigSts: nonqueued-sender-com-spec{data-element=Value, init-value=0}, provided-interface=VeSR2B_y_BPCM_HV_TracBusStsFD5_SigSts
      VeSR2B_y_ProximitySts_FD5: nonqueued-sender-com-spec{data-element=Value, init-value=0}, provided-interface=VeSR2B_y_ProximitySts_FD5
      VeSR2B_y_ProximitySts_FD5_SigSts: nonqueued-sender-com-spec{data-element=Value, init-value=0}, provided-interface=VeSR2B_y_ProximitySts_FD5_SigSts
      VeSR2B_b_MCPA_HV_CnctrOpnRqPFD5: nonqueued-sender-com-spec{data-element=Value, init-value=0}, provided-interface=VeSR2B_b_MCPA_HV_CnctrOpnRqPFD5
      VeSR2B_y_MCPA_HV_CnctrOpnRqPFD5_SigSts: nonqueued-sender-com-spec{data-element=Value, init-value=0}, provided-interface=VeSR2B_y_MCPA_HV_CnctrOpnRqPFD5_SigSts
      VeSR2B_M_MCPA_MaxTorq_P_FD5: nonqueued-sender-com-spec{data-element=Value, init-value=0}, provided-interface=VeSR2B_M_MCPA_MaxTorq_P_FD5
      VeSR2B_y_MCPA_MaxTorq_P_FD5_SigSts: nonqueued-sender-com-spec{data-element=Value, init-value=0}, provided-interface=VeSR2B_y_MCPA_MaxTorq_P_FD5_SigSts
      VeSR2B_M_MCPA_MinTorq_P_FD5: nonqueued-sender-com-spec{data-element=Value, init-value=0}, provided-interface=VeSR2B_M_MCPA_MinTorq_P_FD5
      VeSR2B_y_MCPA_MinTorq_P_FD5_SigSts: nonqueued-sender-com-spec{data-element=Value, init-value=0}, provided-interface=VeSR2B_y_MCPA_MinTorq_P_FD5_SigSts
      VeSR2B_n_MCPA_RPM_P_FD5: nonqueued-sender-com-spec{data-element=Value, init-value=0}, provided-interface=VeSR2B_n_MCPA_RPM_P_FD5
      VeSR2B_y_MCPA_RPM_P_FD5_SigSts: nonqueued-sender-com-spec{data-element=Value, init-value=0}, provided-interface=VeSR2B_y_MCPA_RPM_P_FD5_SigSts
      VeSR2B_b_MCPA_RPM_V_P_FD5: nonqueued-sender-com-spec{data-element=Value, init-value=0}, provided-interface=VeSR2B_b_MCPA_RPM_V_P_FD5
      VeSR2B_y_MCPA_RPM_V_P_FD5_SigSts: nonqueued-sender-com-spec{data-element=Value, init-value=0}, provided-interface=VeSR2B_y_MCPA_RPM_V_P_FD5_SigSts
      VeSR2B_T_MCPA_Temp_P_FD5: nonqueued-sender-com-spec{data-element=Value, init-value=0}, provided-interface=VeSR2B_T_MCPA_Temp_P_FD5
      VeSR2B_y_MCPA_Temp_P_FD5_SigSts: nonqueued-sender-com-spec{data-element=Value, init-value=0}, provided-interface=VeSR2B_y_MCPA_Temp_P_FD5_SigSts
      VeSR2B_M_MCPA_TrqAchvdAEMDPFD5: nonqueued-sender-com-spec{data-element=Value, init-value=0}, provided-interface=VeSR2B_M_MCPA_TrqAchvdAEMDPFD5
      VeSR2B_y_MCPA_TrqAchvdAEMDPFD5_SigSts: nonqueued-sender-com-spec{data-element=Value, init-value=0}, provided-interface=VeSR2B_y_MCPA_TrqAchvdAEMDPFD5_SigSts
      VeSR2B_b_MCPA_TrqAchvdAEMDVPFD5: nonqueued-sender-com-spec{data-element=Value, init-value=0}, provided-interface=VeSR2B_b_MCPA_TrqAchvdAEMDVPFD5
      VeSR2B_y_MCPA_TrqAchvdAEMDVPFD5_SigSts: nonqueued-sender-com-spec{data-element=Value, init-value=0}, provided-interface=VeSR2B_y_MCPA_TrqAchvdAEMDVPFD5_SigSts
      VeSR2B_M_MCPA_Torque_AchvdPFD5: nonqueued-sender-com-spec{data-element=Value, init-value=0}, provided-interface=VeSR2B_M_MCPA_Torque_AchvdPFD5
      VeSR2B_y_MCPA_Torque_AchvdPFD5_SigSts: nonqueued-sender-com-spec{data-element=Value, init-value=0}, provided-interface=VeSR2B_y_MCPA_Torque_AchvdPFD5_SigSts
      VeSR2B_b_MCPA_Trque_AchvdVPFD5: nonqueued-sender-com-spec{data-element=Value, init-value=0}, provided-interface=VeSR2B_b_MCPA_Trque_AchvdVPFD5
      VeSR2B_y_MCPA_Trque_AchvdVPFD5_SigSts: nonqueued-sender-com-spec{data-element=Value, init-value=0}, provided-interface=VeSR2B_y_MCPA_Trque_AchvdVPFD5_SigSts
      VeSR2B_b_MCPB_HV_CnctrOpnRqPFD5: nonqueued-sender-com-spec{data-element=Value, init-value=0}, provided-interface=VeSR2B_b_MCPB_HV_CnctrOpnRqPFD5
      VeSR2B_y_MCPB_HV_CnctrOpnRqPFD5_SigSts: nonqueued-sender-com-spec{data-element=Value, init-value=0}, provided-interface=VeSR2B_y_MCPB_HV_CnctrOpnRqPFD5_SigSts
      VeSR2B_M_MCPB_MaxTorq_P_FD5: nonqueued-sender-com-spec{data-element=Value, init-value=0}, provided-interface=VeSR2B_M_MCPB_MaxTorq_P_FD5
      VeSR2B_y_MCPB_MaxTorq_P_FD5_SigSts: nonqueued-sender-com-spec{data-element=Value, init-value=0}, provided-interface=VeSR2B_y_MCPB_MaxTorq_P_FD5_SigSts
      VeSR2B_M_MCPB_MinTorq_P_FD5: nonqueued-sender-com-spec{data-element=Value, init-value=0}, provided-interface=VeSR2B_M_MCPB_MinTorq_P_FD5
      VeSR2B_y_MCPB_MinTorq_P_FD5_SigSts: nonqueued-sender-com-spec{data-element=Value, init-value=0}, provided-interface=VeSR2B_y_MCPB_MinTorq_P_FD5_SigSts
      VeSR2B_y_MCPB_MtrIndex_P_FD5: nonqueued-sender-com-spec{data-element=Value, init-value=0}, provided-interface=VeSR2B_y_MCPB_MtrIndex_P_FD5
      VeSR2B_y_MCPB_MtrIndex_P_FD5_SigSts: nonqueued-sender-com-spec{data-element=Value, init-value=0}, provided-interface=VeSR2B_y_MCPB_MtrIndex_P_FD5_SigSts
      VeSR2B_n_MCPB_RPM_P_FD5: nonqueued-sender-com-spec{data-element=Value, init-value=0}, provided-interface=VeSR2B_n_MCPB_RPM_P_FD5
      VeSR2B_y_MCPB_RPM_P_FD5_SigSts: nonqueued-sender-com-spec{data-element=Value, init-value=0}, provided-interface=VeSR2B_y_MCPB_RPM_P_FD5_SigSts
      VeSR2B_b_MCPB_RPM_V_P_FD5: nonqueued-sender-com-spec{data-element=Value, init-value=0}, provided-interface=VeSR2B_b_MCPB_RPM_V_P_FD5
      VeSR2B_y_MCPB_RPM_V_P_FD5_SigSts: nonqueued-sender-com-spec{data-element=Value, init-value=0}, provided-interface=VeSR2B_y_MCPB_RPM_V_P_FD5_SigSts
      VeSR2B_y_MCPB_Temp_P_FD5: nonqueued-sender-com-spec{data-element=Value, init-value=0}, provided-interface=VeSR2B_y_MCPB_Temp_P_FD5
      VeSR2B_y_MCPB_Temp_P_FD5_SigSts: nonqueued-sender-com-spec{data-element=Value, init-value=0}, provided-interface=VeSR2B_y_MCPB_Temp_P_FD5_SigSts
      VeSR2B_M_MCPB_TrqAchvd_AEMDPFD5: nonqueued-sender-com-spec{data-element=Value, init-value=0}, provided-interface=VeSR2B_M_MCPB_TrqAchvd_AEMDPFD5
      VeSR2B_y_MCPB_TrqAchvd_AEMDPFD5_SigSts: nonqueued-sender-com-spec{data-element=Value, init-value=0}, provided-interface=VeSR2B_y_MCPB_TrqAchvd_AEMDPFD5_SigSts
      VeSR2B_b_MCPB_TrqAchvdAEMDVPFD5: nonqueued-sender-com-spec{data-element=Value, init-value=0}, provided-interface=VeSR2B_b_MCPB_TrqAchvdAEMDVPFD5
      VeSR2B_y_MCPB_TrqAchvdAEMDVPFD5_SigSts: nonqueued-sender-com-spec{data-element=Value, init-value=0}, provided-interface=VeSR2B_y_MCPB_TrqAchvdAEMDVPFD5_SigSts
      VeSR2B_M_MCPB_Trq_Achved_P_FD5: nonqueued-sender-com-spec{data-element=Value, init-value=0}, provided-interface=VeSR2B_M_MCPB_Trq_Achved_P_FD5
      VeSR2B_y_MCPB_Trq_Achved_P_FD5_SigSts: nonqueued-sender-com-spec{data-element=Value, init-value=0}, provided-interface=VeSR2B_y_MCPB_Trq_Achved_P_FD5_SigSts
      VeSR2B_b_MCPB_Trq_Achved_V_PFD5: nonqueued-sender-com-spec{data-element=Value, init-value=0}, provided-interface=VeSR2B_b_MCPB_Trq_Achved_V_PFD5
      VeSR2B_y_MCPB_Trq_Achved_V_PFD5_SigSts: nonqueued-sender-com-spec{data-element=Value, init-value=0}, provided-interface=VeSR2B_y_MCPB_Trq_Achved_V_PFD5_SigSts
